AUTOSAR XML (schema 4-2-2)
package /STELLANTIS/EPT/ASWCs
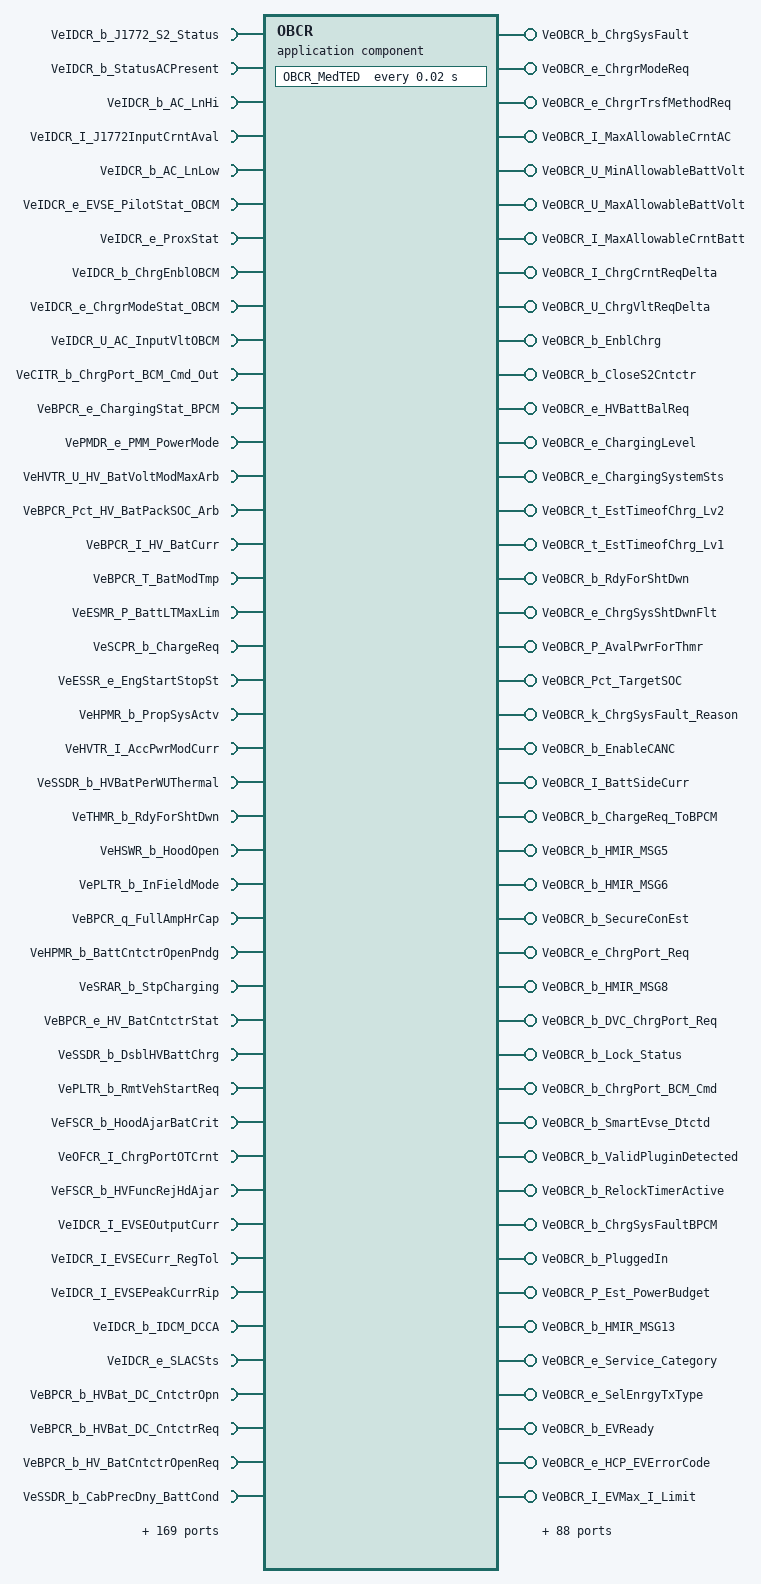
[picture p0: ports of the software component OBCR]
  application sw component type OBCR
    179 x require port:
      VeIDCR_b_J1772_S2_Status: variation-point={short-label=vpVeIDCR_b_J1772_S2_Status, sw-syscond=1}, nonqueued-receiver-com-spec{data-element=Value, init-value=0}, required-interface=VeIDCR_b_J1772_S2_Status
      VeIDCR_b_StatusACPresent: variation-point={short-label=vpVeIDCR_b_StatusACPresent, sw-syscond=1}, nonqueued-receiver-com-spec{data-element=Value, init-value=0}, required-interface=VeIDCR_b_StatusACPresent
      VeIDCR_b_AC_LnHi: variation-point={short-label=vpVeIDCR_b_AC_LnHi, sw-syscond=1}, nonqueued-receiver-com-spec{data-element=Value, init-value=0}, required-interface=VeIDCR_b_AC_LnHi
      VeIDCR_I_J1772InputCrntAval: variation-point={short-label=vpVeIDCR_I_J1772InputCrntAval, sw-syscond=1}, nonqueued-receiver-com-spec{data-element=Value, init-value=0}, required-interface=VeIDCR_I_J1772InputCrntAval
      VeIDCR_b_AC_LnLow: variation-point={short-label=vpVeIDCR_b_AC_LnLow, sw-syscond=1}, nonqueued-receiver-com-spec{data-element=Value, init-value=0}, required-interface=VeIDCR_b_AC_LnLow
      VeIDCR_e_EVSE_PilotStat_OBCM: nonqueued-receiver-com-spec{data-element=Value, init-value=CeOBCR_e_NO_EVSE_OBCM}, required-interface=VeIDCR_e_EVSE_PilotStat_OBCM
      VeIDCR_e_ProxStat: nonqueued-receiver-com-spec{data-element=Value, init-value=CeOBCR_e_ProxLo_OBCM}, required-interface=VeIDCR_e_ProxStat
      VeIDCR_b_ChrgEnblOBCM: nonqueued-receiver-com-spec{data-element=Value, init-value=0}, required-interface=VeIDCR_b_ChrgEnblOBCM
      VeIDCR_e_ChrgrModeStat_OBCM: variation-point={short-label=vpVeIDCR_e_ChrgrModeStat_OBCM, sw-syscond=1}, nonqueued-receiver-com-spec{data-element=Value, init-value=CeOBCR_e_Idle_OBCM}, required-interface=VeIDCR_e_ChrgrModeStat_OBCM
      VeIDCR_U_AC_InputVltOBCM: variation-point={short-label=vpVeIDCR_U_AC_InputVltOBCM, sw-syscond=1}, nonqueued-receiver-com-spec{data-element=Value, init-value=0}, required-interface=VeIDCR_U_AC_InputVltOBCM
      VeCITR_b_ChrgPort_BCM_Cmd_Out: variation-point={short-label=vpVeCITR_b_ChrgPort_BCM_Cmd_Out, sw-syscond=1}, nonqueued-receiver-com-spec{data-element=Value, init-value=0}, required-interface=VeCITR_b_ChrgPort_BCM_Cmd_Out
      VeBPCR_e_ChargingStat_BPCM: nonqueued-receiver-com-spec{data-element=Value, init-value=CeOBCR_e_BattNotReady}, required-interface=VeBPCR_e_ChargingStat_BPCM
      VePMDR_e_PMM_PowerMode: variation-point={short-label=vpVePMDR_e_PMM_PowerMode, sw-syscond=1}, nonqueued-receiver-com-spec{data-element=Value, init-value=CePMDR_e_PowerMode_Off}, required-interface=VePMDR_e_PMM_PowerMode
      VeHVTR_U_HV_BatVoltModMaxArb: nonqueued-receiver-com-spec{data-element=Value, init-value=0}, required-interface=VeHVTR_U_HV_BatVoltModMaxArb
      VeBPCR_Pct_HV_BatPackSOC_Arb: variation-point={short-label=vpVeBPCR_Pct_HV_BatPackSOC_Arb, sw-syscond=1}, nonqueued-receiver-com-spec{data-element=Value, init-value=0}, required-interface=VeBPCR_Pct_HV_BatPackSOC_Arb
      VeBPCR_I_HV_BatCurr: variation-point={short-label=vpVeBPCR_I_HV_BatCurr, sw-syscond=1}, nonqueued-receiver-com-spec{data-element=Value, init-value=0}, required-interface=VeBPCR_I_HV_BatCurr
      VeBPCR_T_BatModTmp: variation-point={short-label=vpVeBPCR_T_BatModTmp, sw-syscond=1}, nonqueued-receiver-com-spec{data-element=Value, init-value=0}, required-interface=VeBPCR_T_BatModTmp
      VeESMR_P_BattLTMaxLim: variation-point={short-label=vpVeESMR_P_BattLTMaxLim, sw-syscond=1}, nonqueued-receiver-com-spec{data-element=Value, init-value=0}, required-interface=VeESMR_P_BattLTMaxLim
      VeSCPR_b_ChargeReq: nonqueued-receiver-com-spec{data-element=Value, init-value=0}, required-interface=VeSCPR_b_ChargeReq
      VeESSR_e_EngStartStopSt: variation-point={short-label=vpVeESSR_e_EngStartStopSt, sw-syscond=1}, nonqueued-receiver-com-spec{data-element=Value, init-value=CeESSR_e_EngOff}, required-interface=VeESSR_e_EngStartStopSt
      VeHPMR_b_PropSysActv: nonqueued-receiver-com-spec{data-element=Value, init-value=0}, required-interface=VeHPMR_b_PropSysActv
      VeHVTR_I_AccPwrModCurr: nonqueued-receiver-com-spec{data-element=Value, init-value=0}, required-interface=VeHVTR_I_AccPwrModCurr
      VeSSDR_b_HVBatPerWUThermal: nonqueued-receiver-com-spec{data-element=Value, init-value=0}, required-interface=VeSSDR_b_HVBatPerWUThermal
      VeTHMR_b_RdyForShtDwn: nonqueued-receiver-com-spec{data-element=Value, init-value=0}, required-interface=VeTHMR_b_RdyForShtDwn
      VeHSWR_b_HoodOpen: nonqueued-receiver-com-spec{data-element=Value, init-value=0}, required-interface=VeHSWR_b_HoodOpen
      VePLTR_b_InFieldMode: nonqueued-receiver-com-spec{data-element=Value, init-value=0}, required-interface=VePLTR_b_InFieldMode
      VeBPCR_q_FullAmpHrCap: nonqueued-receiver-com-spec{data-element=Value, init-value=0}, required-interface=VeBPCR_q_FullAmpHrCap
      VeHPMR_b_BattCntctrOpenPndg: variation-point={short-label=vpVeHPMR_b_BattCntctrOpenPndg, sw-syscond=1}, nonqueued-receiver-com-spec{data-element=Value, init-value=0}, required-interface=VeHPMR_b_BattCntctrOpenPndg
      VeSRAR_b_StpCharging: variation-point={short-label=vpVeSRAR_b_StpCharging, sw-syscond=1}, nonqueued-receiver-com-spec{data-element=Value, init-value=0}, required-interface=VeSRAR_b_StpCharging
      VeBPCR_e_HV_BatCntctrStat: variation-point={short-label=vpVeBPCR_e_HV_BatCntctrStat, sw-syscond=1}, nonqueued-receiver-com-spec{data-element=Value, init-value=CeHVTR_e_Open}, required-interface=VeBPCR_e_HV_BatCntctrStat
      VeSSDR_b_DsblHVBattChrg: variation-point={short-label=vpVeSSDR_b_DsblHVBattChrg, sw-syscond=1}, nonqueued-receiver-com-spec{data-element=Value, init-value=0}, required-interface=VeSSDR_b_DsblHVBattChrg
      VePLTR_b_RmtVehStartReq: variation-point={short-label=vpVePLTR_b_RmtVehStartReq, sw-syscond=1}, nonqueued-receiver-com-spec{data-element=Value, init-value=0}, required-interface=VePLTR_b_RmtVehStartReq
      VeFSCR_b_HoodAjarBatCrit: nonqueued-receiver-com-spec{data-element=Value, init-value=0}, required-interface=VeFSCR_b_HoodAjarBatCrit
      VeOFCR_I_ChrgPortOTCrnt: variation-point={short-label=vpVeOFCR_I_ChrgPortOTCrnt, sw-syscond=1}, nonqueued-receiver-com-spec{data-element=Value, init-value=0}, required-interface=VeOFCR_I_ChrgPortOTCrnt
      VeFSCR_b_HVFuncRejHdAjar: variation-point={short-label=vpVeFSCR_b_HVFuncRejHdAjar, sw-syscond=1}, nonqueued-receiver-com-spec{data-element=Value, init-value=0}, required-interface=VeFSCR_b_HVFuncRejHdAjar
      VeIDCR_I_EVSEOutputCurr: nonqueued-receiver-com-spec{data-element=Value, init-value=0}, required-interface=VeIDCR_I_EVSEOutputCurr
      VeIDCR_I_EVSECurr_RegTol: nonqueued-receiver-com-spec{data-element=Value, init-value=0}, required-interface=VeIDCR_I_EVSECurr_RegTol
      VeIDCR_I_EVSEPeakCurrRip: nonqueued-receiver-com-spec{data-element=Value, init-value=0}, required-interface=VeIDCR_I_EVSEPeakCurrRip
      VeIDCR_b_IDCM_DCCA: nonqueued-receiver-com-spec{data-element=Value, init-value=0}, required-interface=VeIDCR_b_IDCM_DCCA
      VeIDCR_e_SLACSts: nonqueued-receiver-com-spec{data-element=Value, init-value=CeIDCR_e_SLACSts_EVSE_NtFnd}, required-interface=VeIDCR_e_SLACSts
      VeBPCR_b_HVBat_DC_CntctrOpn: nonqueued-receiver-com-spec{data-element=Value, init-value=0}, required-interface=VeBPCR_b_HVBat_DC_CntctrOpn
      VeBPCR_b_HVBat_DC_CntctrReq: nonqueued-receiver-com-spec{data-element=Value, init-value=0}, required-interface=VeBPCR_b_HVBat_DC_CntctrReq
      VeBPCR_b_HV_BatCntctrOpenReq: nonqueued-receiver-com-spec{data-element=Value, init-value=0}, required-interface=VeBPCR_b_HV_BatCntctrOpenReq
      VeSSDR_b_CabPrecDny_BattCond: nonqueued-receiver-com-spec{data-element=Value, init-value=0}, required-interface=VeSSDR_b_CabPrecDny_BattCond
      VeBPCR_b_HV_BatCntctrOpenPending: nonqueued-receiver-com-spec{data-element=Value, init-value=0}, required-interface=VeBPCR_b_HV_BatCntctrOpenPending
      VePLTR_e_ShippingMode: nonqueued-receiver-com-spec{data-element=Value, init-value=CePLTR_e_ShipingMode_CUST_MD}, required-interface=VePLTR_e_ShippingMode
      VeESMR_Pct_IP_SOCSetPt: variation-point={short-label=vpVeESMR_Pct_IP_SOCSetPt, sw-syscond=1}, nonqueued-receiver-com-spec{data-element=Value, init-value=0}, required-interface=VeESMR_Pct_IP_SOCSetPt
      VeENGR_T_EngCoolantTemp: variation-point={short-label=vpVeENGR_T_EngCoolantTemp, sw-syscond=1}, nonqueued-receiver-com-spec{data-element=Value, init-value=0}, required-interface=VeENGR_T_EngCoolantTemp
      VeENGR_b_ECT_Sgnl_Rcvd: variation-point={short-label=vpVeENGR_b_ECT_Sgnl_Rcvd, sw-syscond=1}, nonqueued-receiver-com-spec{data-element=Value, init-value=0}, required-interface=VeENGR_b_ECT_Sgnl_Rcvd
      VeHMIR_Pct_HVBatSOC_HCP: variation-point={short-label=vpVeHMIR_Pct_HVBatSOC_HCP, sw-syscond=1}, nonqueued-receiver-com-spec{data-element=Value, init-value=0}, required-interface=VeHMIR_Pct_HVBatSOC_HCP
      VeESMR_Pct_Logistics_SOCSetPt: variation-point={short-label=vpVeESMR_Pct_Logistics_SOCSetPt, sw-syscond=1}, nonqueued-receiver-com-spec{data-element=Value, init-value=0}, required-interface=VeESMR_Pct_Logistics_SOCSetPt
      VeIDCR_e_Prox_GBT: nonqueued-receiver-com-spec{data-element=Value, init-value=CeIDCR_e_CC_LO}, required-interface=VeIDCR_e_Prox_GBT
      VeIDCR_e_TxGBTMsgResponse: nonqueued-receiver-com-spec{data-element=Value, init-value=CeIDCR_e_GBTRes_EVSE_Not_Connected}, required-interface=VeIDCR_e_TxGBTMsgResponse
      VeIDCR_e_TxGBTMsgRequest: nonqueued-receiver-com-spec{data-element=Value, init-value=CeIDCR_e_GBTReq_EVSE_Not_Connected}, required-interface=VeIDCR_e_TxGBTMsgRequest
      VeIDCR_b_V2L_Detected: nonqueued-receiver-com-spec{data-element=Value, init-value=0}, required-interface=VeIDCR_b_V2L_Detected
      VeVTLR_e_DschrgOBCMdRq: nonqueued-receiver-com-spec{data-element=Value, init-value=CeOBCR_e_Idle_OBCMdRq}, required-interface=VeVTLR_e_DschrgOBCMdRq
      VeVTLR_b_DschrgS2Cmd: nonqueued-receiver-com-spec{data-element=Value, init-value=0}, required-interface=VeVTLR_b_DschrgS2Cmd
      VeVTLR_e_DschrgSysSts: nonqueued-receiver-com-spec{data-element=Value, init-value=CeVTLR_e_DschrgInactv}, required-interface=VeVTLR_e_DschrgSysSts
      VeFCPR_b_FCPS_H2_RefuelSts: variation-point={short-label=vpVeFCPR_b_FCPS_H2_RefuelSts, sw-syscond=1}, nonqueued-receiver-com-spec{data-element=Value, init-value=0}, required-interface=VeFCPR_b_FCPS_H2_RefuelSts
      VeSSDR_b_KeepHotCold_PCC: variation-point={short-label=vpVeSSDR_b_KeepHotCold_PCC, sw-syscond=1}, nonqueued-receiver-com-spec{data-element=Value, init-value=0}, required-interface=VeSSDR_b_KeepHotCold_PCC
      VeDMAB_y_StatusByte_LostCommBCCM: nonqueued-receiver-com-spec{data-element=Value, init-value=0}, required-interface=VeDMAB_y_StatusByte_LostCommBCCM
      VeDMAB_y_StatusByte_LostCommIDCM: nonqueued-receiver-com-spec{data-element=Value, init-value=0}, required-interface=VeDMAB_y_StatusByte_LostCommIDCM
      VeDMAB_y_StatusByte_LostCommOBCM: nonqueued-receiver-com-spec{data-element=Value, init-value=0}, required-interface=VeDMAB_y_StatusByte_LostCommOBCM
      VeDMAB_y_StatusByte_LostComm_IDCM_CANC11: nonqueued-receiver-com-spec{data-element=Value, init-value=0}, required-interface=VeDMAB_y_StatusByte_LostComm_IDCM_CANC11
      VeINVR_I_MtrA_DC_Crnt: variation-point={short-label=vpVeINVR_I_MtrA_DC_Crnt, sw-syscond=1}, nonqueued-receiver-com-spec{data-element=Value, init-value=0}, required-interface=VeINVR_I_MtrA_DC_Crnt
      VeHVTR_P_HV_AccPwr: variation-point={short-label=vpVeHVTR_P_HV_AccPwr, sw-syscond=1}, nonqueued-receiver-com-spec{data-element=Value, init-value=0}, required-interface=VeHVTR_P_HV_AccPwr
      VeINVR_U_MtrA_DC_Volt: variation-point={short-label=vpVeINVR_U_MtrA_DC_Volt, sw-syscond=1}, nonqueued-receiver-com-spec{data-element=Value, init-value=0}, required-interface=VeINVR_U_MtrA_DC_Volt
      VeHVTR_P_AccPwrModPwr: variation-point={short-label=vpVeHVTR_P_AccPwrModPwr, sw-syscond=1}, nonqueued-receiver-com-spec{data-element=Value, init-value=0}, required-interface=VeHVTR_P_AccPwrModPwr
      VeIDCR_b_V2X_Sts: variation-point={short-label=vpVeIDCR_b_V2X_Sts, sw-syscond=1}, nonqueued-receiver-com-spec{data-element=Value, init-value=0}, required-interface=VeIDCR_b_V2X_Sts
      VeVDVR_b_DschrgS2Cmd: variation-point={short-label=vpVeVDVR_b_DschrgS2Cmd, sw-syscond=1}, nonqueued-receiver-com-spec{data-element=Value, init-value=0}, required-interface=VeVDVR_b_DschrgS2Cmd
      VeVTLR_b_OnboardPP1_Dtctd: nonqueued-receiver-com-spec{data-element=Value, init-value=0}, required-interface=VeVTLR_b_OnboardPP1_Dtctd
      VeVTLR_b_ACSwSts: variation-point={short-label=vpVeVTLR_b_ACSwSts, sw-syscond=1}, nonqueued-receiver-com-spec{data-element=Value, init-value=0}, required-interface=VeVTLR_b_ACSwSts
      VeVDVR_b_V2VChrgPortReq: variation-point={short-label=vpVeVDVR_b_V2VChrgPortReq, sw-syscond=1}, nonqueued-receiver-com-spec{data-element=Value, init-value=0}, required-interface=VeVDVR_b_V2VChrgPortReq
      VeVDVR_b_V2V_Detected: variation-point={short-label=vpVeVDVR_b_V2V_Detected, sw-syscond=1}, nonqueued-receiver-com-spec{data-element=Value, init-value=0}, required-interface=VeVDVR_b_V2V_Detected
      VeVTLR_e_DschrgOBCMdRq_Onboard: nonqueued-receiver-com-spec{data-element=Value, init-value=CeOBCR_e_Idle_OBCMdRq}, required-interface=VeVTLR_e_DschrgOBCMdRq_Onboard
      VeVDVR_e_DschrgOBCMdRq: nonqueued-receiver-com-spec{data-element=Value, init-value=CeOBCR_e_Idle_OBCMdRq}, required-interface=VeVDVR_e_DschrgOBCMdRq
      VeHVTR_U_HvBattVolt_Min: variation-point={short-label=vpVeHVTR_U_HvBattVolt_Min, sw-syscond=1}, nonqueued-receiver-com-spec{data-element=Value, init-value=0}, required-interface=VeHVTR_U_HvBattVolt_Min
      VeTIMR_e_RacePrepRaceTypeSts: variation-point={short-label=vpVeTIMR_e_RacePrepRaceTypeSts, sw-syscond=1}, nonqueued-receiver-com-spec{data-element=Value, init-value=CeTIMR_e_RaceType_Drag}, required-interface=VeTIMR_e_RacePrepRaceTypeSts
      VeTIMR_e_RacePrep: variation-point={short-label=vpVeTIMR_e_RacePrep, sw-syscond=1}, nonqueued-receiver-com-spec{data-element=Value, init-value=CeTIMR_e_RacePrep_Off}, required-interface=VeTIMR_e_RacePrep
      VeBPCR_e_HVTracBatCntctrConfig: nonqueued-receiver-com-spec{data-element=Value, init-value=CeBPCR_e_HVTracBatConfig_Closed_Parallel}, required-interface=VeBPCR_e_HVTracBatCntctrConfig
      VeBPCR_b_HV_AuxLoadOffReq: nonqueued-receiver-com-spec{data-element=Value, init-value=0}, required-interface=VeBPCR_b_HV_AuxLoadOffReq
      VeCCCR_b_SOC_LvlSet_80: nonqueued-receiver-com-spec{data-element=Value, init-value=0}, required-interface=VeCCCR_b_SOC_LvlSet_80
      VeCHFR_v_ModifiedVehSpeed: variation-point={short-label=vpVeCHFR_v_ModifiedVehSpeed, sw-syscond=1}, nonqueued-receiver-com-spec{data-element=Value, init-value=0}, required-interface=VeCHFR_v_ModifiedVehSpeed
      VeCHFR_b_ACPrnt_S2Open: variation-point={short-label=vpVeCHFR_b_ACPrnt_S2Open, sw-syscond=1}, nonqueued-receiver-com-spec{data-element=Value, init-value=0}, required-interface=VeCHFR_b_ACPrnt_S2Open
      VeCCCR_I_ChrgTypeHWLim: variation-point={short-label=vpVeCCCR_I_ChrgTypeHWLim, sw-syscond=1}, nonqueued-receiver-com-spec{data-element=Value, init-value=0}, required-interface=VeCCCR_I_ChrgTypeHWLim
      VeCCCR_I_BattCommandedCurr: variation-point={short-label=vpVeCCCR_I_BattCommandedCurr, sw-syscond=1}, nonqueued-receiver-com-spec{data-element=Value, init-value=0}, required-interface=VeCCCR_I_BattCommandedCurr
      VeCPLR_e_ChrgPort_Req: nonqueued-receiver-com-spec{data-element=Value, init-value=CeOBCR_e_PortNoRequest}, required-interface=VeCPLR_e_ChrgPort_Req
      VeCCCR_b_PwrLevActive: variation-point={short-label=vpVeCCCR_b_PwrLevActive, sw-syscond=1}, nonqueued-receiver-com-spec{data-element=Value, init-value=0}, required-interface=VeCCCR_b_PwrLevActive
      VeCCCR_e_PwrLevSet: nonqueued-receiver-com-spec{data-element=Value, init-value=CeOBCR_e_PwrLimReq_SNA}, required-interface=VeCCCR_e_PwrLevSet
      VeCCCR_I_MaxAllowedCurr: nonqueued-receiver-com-spec{data-element=Value, init-value=0}, required-interface=VeCCCR_I_MaxAllowedCurr
      VeCHFR_b_CANC_WU_NCV: variation-point={short-label=vpVeCHFR_b_CANC_WU_NCV, sw-syscond=1}, nonqueued-receiver-com-spec{data-element=Value, init-value=0}, required-interface=VeCHFR_b_CANC_WU_NCV
      VeCCCR_I_HWCurrentBound: variation-point={short-label=vpVeCCCR_I_HWCurrentBound, sw-syscond=1}, nonqueued-receiver-com-spec{data-element=Value, init-value=0}, required-interface=VeCCCR_I_HWCurrentBound
      VeCCCR_I_PLS_ReducedCurr: variation-point={short-label=vpVeCCCR_I_PLS_ReducedCurr, sw-syscond=1}, nonqueued-receiver-com-spec{data-element=Value, init-value=0}, required-interface=VeCCCR_I_PLS_ReducedCurr
      VeCHFR_b_ChrgSysFault: nonqueued-receiver-com-spec{data-element=Value, init-value=0}, required-interface=VeCHFR_b_ChrgSysFault
      VeDCCR_b_V2GPilotEnable: variation-point={short-label=vpVeDCCR_b_V2GPilotEnable, sw-syscond=1}, nonqueued-receiver-com-spec{data-element=Value, init-value=0}, required-interface=VeDCCR_b_V2GPilotEnable
      VeDCCR_e_DCChrgSysStat_SF: variation-point={short-label=vpVeDCCR_e_DCChrgSysStat_SF, sw-syscond=1}, nonqueued-receiver-com-spec{data-element=Value, init-value=CeOBCR_e_DCinit}, required-interface=VeDCCR_e_DCChrgSysStat_SF
      VeCHFR_b_Reset_Charging: variation-point={short-label=vpVeCHFR_b_Reset_Charging, sw-syscond=1}, nonqueued-receiver-com-spec{data-element=Value, init-value=0}, required-interface=VeCHFR_b_Reset_Charging
      VeCHFR_b_GiveUp: variation-point={short-label=vpVeCHFR_b_GiveUp, sw-syscond=1}, nonqueued-receiver-com-spec{data-element=Value, init-value=0}, required-interface=VeCHFR_b_GiveUp
      VeDCCR_e_DCGBTChrgSysStat: variation-point={short-label=vpVeDCCR_e_DCGBTChrgSysStat, sw-syscond=1}, nonqueued-receiver-com-spec{data-element=Value, init-value=CeOBCR_e_DCGBTinit}, required-interface=VeDCCR_e_DCGBTChrgSysStat
      VeDCCR_b_J1772_S2_Close_DC_SF: variation-point={short-label=vpVeDCCR_b_J1772_S2_Close_DC_SF, sw-syscond=1}, nonqueued-receiver-com-spec{data-element=Value, init-value=0}, required-interface=VeDCCR_b_J1772_S2_Close_DC_SF
      VeCHFR_b_ChargingFault: variation-point={short-label=vpVeCHFR_b_ChargingFault, sw-syscond=1}, nonqueued-receiver-com-spec{data-element=Value, init-value=0}, required-interface=VeCHFR_b_ChargingFault
      VeCCCR_b_ChrgCmplteCondtnMet: variation-point={short-label=vpVeCCCR_b_ChrgCmplteCondtnMet, sw-syscond=1}, nonqueued-receiver-com-spec{data-element=Value, init-value=0}, required-interface=VeCCCR_b_ChrgCmplteCondtnMet
      VeCPLR_b_InternalLockReq: variation-point={short-label=vpVeCPLR_b_InternalLockReq, sw-syscond=1}, nonqueued-receiver-com-spec{data-element=Value, init-value=0}, required-interface=VeCPLR_b_InternalLockReq
      VeCPLR_b_RelockTimerActive: nonqueued-receiver-com-spec{data-element=Value, init-value=0}, required-interface=VeCPLR_b_RelockTimerActive
      VeCPLR_b_Lock_Status: nonqueued-receiver-com-spec{data-element=Value, init-value=0}, required-interface=VeCPLR_b_Lock_Status
      VeCPLR_k_ChrgPortEnbl_BSW: nonqueued-receiver-com-spec{data-element=Value, init-value=0}, required-interface=VeCPLR_k_ChrgPortEnbl_BSW
      VeCPLR_b_ChrgPortReq_BSW: nonqueued-receiver-com-spec{data-element=Value, init-value=0}, required-interface=VeCPLR_b_ChrgPortReq_BSW
      VeCPLR_b_DVC_ChrgPort_Req: nonqueued-receiver-com-spec{data-element=Value, init-value=0}, required-interface=VeCPLR_b_DVC_ChrgPort_Req
      VeCPLR_b_HMIR_MSG13: nonqueued-receiver-com-spec{data-element=Value, init-value=0}, required-interface=VeCPLR_b_HMIR_MSG13
      VeCPLR_e_ChargePortLock_Sts: nonqueued-receiver-com-spec{data-element=Value, init-value=CeOBCR_e_PortLockSts_Default}, required-interface=VeCPLR_e_ChargePortLock_Sts
      VeCCCR_I_ChrgCrntReqDelta: nonqueued-receiver-com-spec{data-element=Value, init-value=0}, required-interface=VeCCCR_I_ChrgCrntReqDelta
      VeCCCR_e_HVBattBalReq: nonqueued-receiver-com-spec{data-element=Value, init-value=CeOBCR_e_NoRequest}, required-interface=VeCCCR_e_HVBattBalReq
      VeCCCR_e_BattPckVoltRchd_BST: nonqueued-receiver-com-spec{data-element=Value, init-value=CeOBCR_e_BattPckVolt_NotReached}, required-interface=VeCCCR_e_BattPckVoltRchd_BST
      VeCCCR_e_SOCRchd_BST: nonqueued-receiver-com-spec{data-element=Value, init-value=CeOBCR_e_SOC_NotReached}, required-interface=VeCCCR_e_SOCRchd_BST
      VeCCCR_e_MaxCellVoltRchd_BST: nonqueued-receiver-com-spec{data-element=Value, init-value=CeOBCR_e_MaxCellVolt_NotReached}, required-interface=VeCCCR_e_MaxCellVoltRchd_BST
      VeCCCR_P_PLS_PwrLev{1..5}: nonqueued-receiver-com-spec{data-element=Value, init-value=0}, required-interface=VeCCCR_P_PLS_PwrLev{1..5}
      VeCHFR_U_ChrgVltReqDelta: nonqueued-receiver-com-spec{data-element=Value, init-value=0}, required-interface=VeCHFR_U_ChrgVltReqDelta
      VeCHFR_k_ChrgSysFault_Reason: nonqueued-receiver-com-spec{data-element=Value, init-value=0}, required-interface=VeCHFR_k_ChrgSysFault_Reason
      VeCHFR_I_BattSideCurr: nonqueued-receiver-com-spec{data-element=Value, init-value=0}, required-interface=VeCHFR_I_BattSideCurr
      VeCHFR_b_ChargeReq_ToBPCM: nonqueued-receiver-com-spec{data-element=Value, init-value=0}, required-interface=VeCHFR_b_ChargeReq_ToBPCM
      VeCHFR_b_HMIR_MSG5: nonqueued-receiver-com-spec{data-element=Value, init-value=0}, required-interface=VeCHFR_b_HMIR_MSG5
      VeCHFR_b_HMIR_MSG6: nonqueued-receiver-com-spec{data-element=Value, init-value=0}, required-interface=VeCHFR_b_HMIR_MSG6
      VeCHFR_b_HMIR_MSG8: nonqueued-receiver-com-spec{data-element=Value, init-value=0}, required-interface=VeCHFR_b_HMIR_MSG8
      VeCHFR_b_ChrgSysFaultBPCM: nonqueued-receiver-com-spec{data-element=Value, init-value=0}, required-interface=VeCHFR_b_ChrgSysFaultBPCM
      VeCHFR_K_ChargingFailure{1..5}: nonqueued-receiver-com-spec{data-element=Value, init-value=0}, required-interface=VeCHFR_K_ChargingFailure{1..5}
      VeDCCR_e_Service_Category: nonqueued-receiver-com-spec{data-element=Value, init-value=0}, required-interface=VeDCCR_e_Service_Category
      VeDCCR_e_SelEnrgyTxType: nonqueued-receiver-com-spec{data-element=Value, init-value=0}, required-interface=VeDCCR_e_SelEnrgyTxType
      VeDCCR_b_EVReady: nonqueued-receiver-com-spec{data-element=Value, init-value=0}, required-interface=VeDCCR_b_EVReady
      VeDCCR_e_HCP_EVErrorCode: nonqueued-receiver-com-spec{data-element=Value, init-value=0}, required-interface=VeDCCR_e_HCP_EVErrorCode
      VeDCCR_I_EVMax_I_Limit: nonqueued-receiver-com-spec{data-element=Value, init-value=0}, required-interface=VeDCCR_I_EVMax_I_Limit
      VeDCCR_P_EVMax_P_Limit: nonqueued-receiver-com-spec{data-element=Value, init-value=0}, required-interface=VeDCCR_P_EVMax_P_Limit
      VeDCCR_U_EVMax_V_Limit: nonqueued-receiver-com-spec{data-element=Value, init-value=0}, required-interface=VeDCCR_U_EVMax_V_Limit
      VeDCCR_E_EVEnergyCapacity: nonqueued-receiver-com-spec{data-element=Value, init-value=0}, required-interface=VeDCCR_E_EVEnergyCapacity
      VeDCCR_b_DC_Isolation_Cmd: nonqueued-receiver-com-spec{data-element=Value, init-value=0}, required-interface=VeDCCR_b_DC_Isolation_Cmd
      VeDCCR_e_DC_CntctrCmd: nonqueued-receiver-com-spec{data-element=Value, init-value=CeOBCR_e_DCCntctr_Open}, required-interface=VeDCCR_e_DC_CntctrCmd
      VeDCCR_U_EV_DCTargetVolt: nonqueued-receiver-com-spec{data-element=Value, init-value=0}, required-interface=VeDCCR_U_EV_DCTargetVolt
      VeDCCR_b_WeldChkComplete: nonqueued-receiver-com-spec{data-element=Value, init-value=0}, required-interface=VeDCCR_b_WeldChkComplete
      VeDCCR_b_RdyToChrgSt: nonqueued-receiver-com-spec{data-element=Value, init-value=0}, required-interface=VeDCCR_b_RdyToChrgSt
      VeDCCR_K_SelectedServiceID: nonqueued-receiver-com-spec{data-element=Value, init-value=0}, required-interface=VeDCCR_K_SelectedServiceID
      VeDCCR_e_SelPayOptn: nonqueued-receiver-com-spec{data-element=Value, init-value=CeOBCR_e_NoPaymentSel}, required-interface=VeDCCR_e_SelPayOptn
      VeDCCR_b_HCP_SessionStpCmd: nonqueued-receiver-com-spec{data-element=Value, init-value=0}, required-interface=VeDCCR_b_HCP_SessionStpCmd
      VeDCCR_e_DCChrg_TestSts: nonqueued-receiver-com-spec{data-element=Value, init-value=CeOBCR_e_DCChrg_TestSts_NotInit}, required-interface=VeDCCR_e_DCChrg_TestSts
      VeDCCR_b_DCChrgInitialization: nonqueued-receiver-com-spec{data-element=Value, init-value=0}, required-interface=VeDCCR_b_DCChrgInitialization
      VeDCCR_e_CellVolt_OOR: nonqueued-receiver-com-spec{data-element=Value, init-value=CeOBCR_e_CellVoltStat_Normal}, required-interface=VeDCCR_e_CellVolt_OOR
      VeDCCR_e_ChrgCurr_OOR: nonqueued-receiver-com-spec{data-element=Value, init-value=CeOBCR_e_ChrgCurrStat_Normal}, required-interface=VeDCCR_e_ChrgCurr_OOR
      VeDCCR_e_BattTemp_OOR: nonqueued-receiver-com-spec{data-element=Value, init-value=CeOBCR_e_BattTempStat_Normal}, required-interface=VeDCCR_e_BattTemp_OOR
      VeDCCR_e_SOC_OOR: nonqueued-receiver-com-spec{data-element=Value, init-value=CeOBCR_e_BattSOCStat_Normal}, required-interface=VeDCCR_e_SOC_OOR
      VeDCCR_b_CPIM_Error: nonqueued-receiver-com-spec{data-element=Value, init-value=0}, required-interface=VeDCCR_b_CPIM_Error
      VeDCCR_b_CPIM_OT: nonqueued-receiver-com-spec{data-element=Value, init-value=0}, required-interface=VeDCCR_b_CPIM_OT
      VeDCCR_Pct_BattFullSOC: nonqueued-receiver-com-spec{data-element=Value, init-value=0}, required-interface=VeDCCR_Pct_BattFullSOC
      VeDCCR_b_BattOverVolt: nonqueued-receiver-com-spec{data-element=Value, init-value=0}, required-interface=VeDCCR_b_BattOverVolt
      VeDCCR_b_BattUnderVolt: nonqueued-receiver-com-spec{data-element=Value, init-value=0}, required-interface=VeDCCR_b_BattUnderVolt
      VeDCCR_b_DCGBTReadyToCharge: nonqueued-receiver-com-spec{data-element=Value, init-value=0}, required-interface=VeDCCR_b_DCGBTReadyToCharge
      VeDCCR_b_DCGBTEVChrgPermit: nonqueued-receiver-com-spec{data-element=Value, init-value=0}, required-interface=VeDCCR_b_DCGBTEVChrgPermit
      VeDCCR_T_GBT_MaxBattTempAllwd: nonqueued-receiver-com-spec{data-element=Value, init-value=0}, required-interface=VeDCCR_T_GBT_MaxBattTempAllwd
      VeDCCR_e_GBT_ChrgCntrolMethod: nonqueued-receiver-com-spec{data-element=Value, init-value=CeOBCR_e_ChrgMthd_Init}, required-interface=VeDCCR_e_GBT_ChrgCntrolMethod
      VeDCCR_e_GBT_ChrgrInterrupt: nonqueued-receiver-com-spec{data-element=Value, init-value=CeOBCR_e_NoChrgrInterrupt}, required-interface=VeDCCR_e_GBT_ChrgrInterrupt
      VeDCCR_e_SelectAppProtocol: nonqueued-receiver-com-spec{data-element=Value, init-value=CeOBCR_e_DIN}, required-interface=VeDCCR_e_SelectAppProtocol
      VeDCCR_b_SelectSecProtocol: nonqueued-receiver-com-spec{data-element=Value, init-value=0}, required-interface=VeDCCR_b_SelectSecProtocol
      VeDCCR_e_ChargeProgress: nonqueued-receiver-com-spec{data-element=Value, init-value=CeOBCR_e_No_Request}, required-interface=VeDCCR_e_ChargeProgress
      VeDCCR_e_DC_ChrgTypeCmd: nonqueued-receiver-com-spec{data-element=Value, init-value=CeOBCR_e_DC_ChrgType_Null}, required-interface=VeDCCR_e_DC_ChrgTypeCmd
      VeVDVR_b_Secure_V2VConnected: variation-point={short-label=vpVeVDVR_b_Secure_V2VConnected, sw-syscond=1}, nonqueued-receiver-com-spec{data-element=Value, init-value=0}, required-interface=VeVDVR_b_Secure_V2VConnected
      VeVDVR_b_Secure_V2LConnected: variation-point={short-label=vpVeVDVR_b_Secure_V2LConnected, sw-syscond=1}, nonqueued-receiver-com-spec{data-element=Value, init-value=0}, required-interface=VeVDVR_b_Secure_V2LConnected
      VeVTHR_b_Rdy4shutdown: variation-point={short-label=vpVeVTHR_b_Rdy4shutdown, sw-syscond=1}, nonqueued-receiver-com-spec{data-element=Value, init-value=0}, required-interface=VeVTHR_b_Rdy4shutdown
      VeVTHR_b_V2H_Active: variation-point={short-label=vpVeVTHR_b_V2H_Active, sw-syscond=1}, nonqueued-receiver-com-spec{data-element=Value, init-value=0}, required-interface=VeVTHR_b_V2H_Active
      VeDCCR_b_PnCFailure: nonqueued-receiver-com-spec{data-element=Value, init-value=0}, required-interface=VeDCCR_b_PnCFailure
      VeDCCR_b_PnCRetryFail: nonqueued-receiver-com-spec{data-element=Value, init-value=0}, required-interface=VeDCCR_b_PnCRetryFail
      VeDCCR_e_Protocol_Priority{1..3}: nonqueued-receiver-com-spec{data-element=Value, init-value=CeOBCR_e_No_Protocol}, required-interface=VeDCCR_e_Protocol_Priority{1..3}
      VeDCCR_k_MaxEntriesSASScheduleTuple: nonqueued-receiver-com-spec{data-element=Value, init-value=0}, required-interface=VeDCCR_k_MaxEntriesSASScheduleTuple
    133 x provide port:
      VeOBCR_b_ChrgSysFault: nonqueued-sender-com-spec{data-element=Value, init-value=0}, provided-interface=VeOBCR_b_ChrgSysFault
      VeOBCR_e_ChrgrModeReq: nonqueued-sender-com-spec{data-element=Value, init-value=CeOBCR_e_Idle_OBCMdRq}, provided-interface=VeOBCR_e_ChrgrModeReq
      VeOBCR_e_ChrgrTrsfMethodReq: nonqueued-sender-com-spec{data-element=Value, init-value=CeOBCR_e_Current}, provided-interface=VeOBCR_e_ChrgrTrsfMethodReq
      VeOBCR_I_MaxAllowableCrntAC: nonqueued-sender-com-spec{data-element=Value, init-value=0}, provided-interface=VeOBCR_I_MaxAllowableCrntAC
      VeOBCR_U_MinAllowableBattVolt: nonqueued-sender-com-spec{data-element=Value, init-value=0}, provided-interface=VeOBCR_U_MinAllowableBattVolt
      VeOBCR_U_MaxAllowableBattVolt: nonqueued-sender-com-spec{data-element=Value, init-value=0}, provided-interface=VeOBCR_U_MaxAllowableBattVolt
      VeOBCR_I_MaxAllowableCrntBatt: nonqueued-sender-com-spec{data-element=Value, init-value=0}, provided-interface=VeOBCR_I_MaxAllowableCrntBatt
      VeOBCR_I_ChrgCrntReqDelta: nonqueued-sender-com-spec{data-element=Value, init-value=0}, provided-interface=VeOBCR_I_ChrgCrntReqDelta
      VeOBCR_U_ChrgVltReqDelta: nonqueued-sender-com-spec{data-element=Value, init-value=0}, provided-interface=VeOBCR_U_ChrgVltReqDelta
      VeOBCR_b_EnblChrg: nonqueued-sender-com-spec{data-element=Value, init-value=0}, provided-interface=VeOBCR_b_EnblChrg
      VeOBCR_b_CloseS2Cntctr: nonqueued-sender-com-spec{data-element=Value, init-value=0}, provided-interface=VeOBCR_b_CloseS2Cntctr
      VeOBCR_e_HVBattBalReq: nonqueued-sender-com-spec{data-element=Value, init-value=CeOBCR_e_NoRequest}, provided-interface=VeOBCR_e_HVBattBalReq
      VeOBCR_e_ChargingLevel: nonqueued-sender-com-spec{data-element=Value, init-value=CeOBCR_e_ChargingLvlDefault}, provided-interface=VeOBCR_e_ChargingLevel
      VeOBCR_e_ChargingSystemSts: nonqueued-sender-com-spec{data-element=Value, init-value=CeOBCR_e_NotCharging}, provided-interface=VeOBCR_e_ChargingSystemSts
      VeOBCR_t_EstTimeofChrg_Lv2: nonqueued-sender-com-spec{data-element=Value, init-value=0}, provided-interface=VeOBCR_t_EstTimeofChrg_Lv2
      VeOBCR_t_EstTimeofChrg_Lv1: nonqueued-sender-com-spec{data-element=Value, init-value=0}, provided-interface=VeOBCR_t_EstTimeofChrg_Lv1
      VeOBCR_b_RdyForShtDwn: nonqueued-sender-com-spec{data-element=Value, init-value=0}, provided-interface=VeOBCR_b_RdyForShtDwn
      VeOBCR_e_ChrgSysShtDwnFlt: nonqueued-sender-com-spec{data-element=Value, init-value=CeSRAR_e_NoFlt}, provided-interface=VeOBCR_e_ChrgSysShtDwnFlt
      VeOBCR_P_AvalPwrForThmr: nonqueued-sender-com-spec{data-element=Value, init-value=0}, provided-interface=VeOBCR_P_AvalPwrForThmr
      VeOBCR_Pct_TargetSOC: nonqueued-sender-com-spec{data-element=Value, init-value=0}, provided-interface=VeOBCR_Pct_TargetSOC
      VeOBCR_k_ChrgSysFault_Reason: nonqueued-sender-com-spec{data-element=Value, init-value=0}, provided-interface=VeOBCR_k_ChrgSysFault_Reason
      VeOBCR_b_EnableCANC: nonqueued-sender-com-spec{data-element=Value, init-value=0}, provided-interface=VeOBCR_b_EnableCANC
      VeOBCR_I_BattSideCurr: nonqueued-sender-com-spec{data-element=Value, init-value=0}, provided-interface=VeOBCR_I_BattSideCurr
      VeOBCR_b_ChargeReq_ToBPCM: nonqueued-sender-com-spec{data-element=Value, init-value=0}, provided-interface=VeOBCR_b_ChargeReq_ToBPCM
      VeOBCR_b_HMIR_MSG5: nonqueued-sender-com-spec{data-element=Value, init-value=0}, provided-interface=VeOBCR_b_HMIR_MSG5
      VeOBCR_b_HMIR_MSG6: nonqueued-sender-com-spec{data-element=Value, init-value=0}, provided-interface=VeOBCR_b_HMIR_MSG6
      VeOBCR_b_SecureConEst: nonqueued-sender-com-spec{data-element=Value, init-value=0}, provided-interface=VeOBCR_b_SecureConEst
      VeOBCR_e_ChrgPort_Req: nonqueued-sender-com-spec{data-element=Value, init-value=CeOBCR_e_PortNoRequest}, provided-interface=VeOBCR_e_ChrgPort_Req
      VeOBCR_b_HMIR_MSG8: nonqueued-sender-com-spec{data-element=Value, init-value=0}, provided-interface=VeOBCR_b_HMIR_MSG8
      VeOBCR_b_DVC_ChrgPort_Req: nonqueued-sender-com-spec{data-element=Value, init-value=0}, provided-interface=VeOBCR_b_DVC_ChrgPort_Req
      VeOBCR_b_Lock_Status: nonqueued-sender-com-spec{data-element=Value, init-value=0}, provided-interface=VeOBCR_b_Lock_Status
      VeOBCR_b_ChrgPort_BCM_Cmd: nonqueued-sender-com-spec{data-element=Value, init-value=0}, provided-interface=VeOBCR_b_ChrgPort_BCM_Cmd
      VeOBCR_b_SmartEvse_Dtctd: nonqueued-sender-com-spec{data-element=Value, init-value=0}, provided-interface=VeOBCR_b_SmartEvse_Dtctd
      VeOBCR_b_ValidPluginDetected: nonqueued-sender-com-spec{data-element=Value, init-value=0}, provided-interface=VeOBCR_b_ValidPluginDetected
      VeOBCR_b_RelockTimerActive: nonqueued-sender-com-spec{data-element=Value, init-value=0}, provided-interface=VeOBCR_b_RelockTimerActive
      VeOBCR_b_ChrgSysFaultBPCM: nonqueued-sender-com-spec{data-element=Value, init-value=0}, provided-interface=VeOBCR_b_ChrgSysFaultBPCM
      VeOBCR_b_PluggedIn: nonqueued-sender-com-spec{data-element=Value, init-value=0}, provided-interface=VeOBCR_b_PluggedIn
      VeOBCR_P_Est_PowerBudget: nonqueued-sender-com-spec{data-element=Value, init-value=0}, provided-interface=VeOBCR_P_Est_PowerBudget
      VeOBCR_b_HMIR_MSG13: nonqueued-sender-com-spec{data-element=Value, init-value=0}, provided-interface=VeOBCR_b_HMIR_MSG13
      VeOBCR_e_Service_Category: nonqueued-sender-com-spec{data-element=Value, init-value=0}, provided-interface=VeOBCR_e_Service_Category
      VeOBCR_e_SelEnrgyTxType: nonqueued-sender-com-spec{data-element=Value, init-value=0}, provided-interface=VeOBCR_e_SelEnrgyTxType
      VeOBCR_b_EVReady: nonqueued-sender-com-spec{data-element=Value, init-value=0}, provided-interface=VeOBCR_b_EVReady
      VeOBCR_e_HCP_EVErrorCode: nonqueued-sender-com-spec{data-element=Value, init-value=0}, provided-interface=VeOBCR_e_HCP_EVErrorCode
      VeOBCR_I_EVMax_I_Limit: nonqueued-sender-com-spec{data-element=Value, init-value=0}, provided-interface=VeOBCR_I_EVMax_I_Limit
      VeOBCR_P_EVMax_P_Limit: nonqueued-sender-com-spec{data-element=Value, init-value=0}, provided-interface=VeOBCR_P_EVMax_P_Limit
      VeOBCR_U_EVMax_V_Limit: nonqueued-sender-com-spec{data-element=Value, init-value=0}, provided-interface=VeOBCR_U_EVMax_V_Limit
      VeOBCR_E_EVEnergyCapacity: nonqueued-sender-com-spec{data-element=Value, init-value=0}, provided-interface=VeOBCR_E_EVEnergyCapacity
      VeOBCR_E_EVEnergyRequest: nonqueued-sender-com-spec{data-element=Value, init-value=0}, provided-interface=VeOBCR_E_EVEnergyRequest
      VeOBCR_b_DC_Isolation_Cmd: nonqueued-sender-com-spec{data-element=Value, init-value=0}, provided-interface=VeOBCR_b_DC_Isolation_Cmd
      VeOBCR_e_DC_CntctrCmd: nonqueued-sender-com-spec{data-element=Value, init-value=CeOBCR_e_DCCntctr_Open}, provided-interface=VeOBCR_e_DC_CntctrCmd
      VeOBCR_U_EV_DCTargetVolt: nonqueued-sender-com-spec{data-element=Value, init-value=0}, provided-interface=VeOBCR_U_EV_DCTargetVolt
      VeOBCR_b_WeldChkComplete: nonqueued-sender-com-spec{data-element=Value, init-value=0}, provided-interface=VeOBCR_b_WeldChkComplete
      VeOBCR_b_RdyToChrgSt: nonqueued-sender-com-spec{data-element=Value, init-value=0}, provided-interface=VeOBCR_b_RdyToChrgSt
      VeOBCR_b_ChargingComplete: nonqueued-sender-com-spec{data-element=Value, init-value=0}, provided-interface=VeOBCR_b_ChargingComplete
      VeOBCR_t_RemTimeToFullSOC: nonqueued-sender-com-spec{data-element=Value, init-value=0}, provided-interface=VeOBCR_t_RemTimeToFullSOC
      VeOBCR_K_SelectedServiceID: nonqueued-sender-com-spec{data-element=Value, init-value=0}, provided-interface=VeOBCR_K_SelectedServiceID
      VeOBCR_e_SelPayOptn: nonqueued-sender-com-spec{data-element=Value, init-value=CeOBCR_e_NoPaymentSel}, provided-interface=VeOBCR_e_SelPayOptn
      VeOBCR_b_HCP_SessionStpCmd: nonqueued-sender-com-spec{data-element=Value, init-value=0}, provided-interface=VeOBCR_b_HCP_SessionStpCmd
      VeOBCR_e_HCP_DC_Retry: nonqueued-sender-com-spec{data-element=Value, init-value=CeOBCR_e_No_Retry_Command}, provided-interface=VeOBCR_e_HCP_DC_Retry
      VeOBCR_e_ChargeType: nonqueued-sender-com-spec{data-element=Value, init-value=CeOBCR_e_AC}, provided-interface=VeOBCR_e_ChargeType
      VeOBCR_e_DCChrg_TestSts: nonqueued-sender-com-spec{data-element=Value, init-value=CeOBCR_e_DCChrg_TestSts_NotInit}, provided-interface=VeOBCR_e_DCChrg_TestSts
      VeOBCR_K_ChargingFailure{1..5}: nonqueued-sender-com-spec{data-element=Value, init-value=0}, provided-interface=VeOBCR_K_ChargingFailure{1..5}
      VeOBCR_b_ChrgPortReq_BSW: nonqueued-sender-com-spec{data-element=Value, init-value=0}, provided-interface=VeOBCR_b_ChrgPortReq_BSW
      VeOBCR_k_ChrgPortEnbl_BSW: nonqueued-sender-com-spec{data-element=Value, init-value=0}, provided-interface=VeOBCR_k_ChrgPortEnbl_BSW
      VeOBCR_t_EstTimeDCFastChrg_100: nonqueued-sender-com-spec{data-element=Value, init-value=0}, provided-interface=VeOBCR_t_EstTimeDCFastChrg_100
      VeOBCR_t_EstTimeDCFastChrg_80: nonqueued-sender-com-spec{data-element=Value, init-value=0}, provided-interface=VeOBCR_t_EstTimeDCFastChrg_80
      VeOBCR_I_MaxAllowedCurr: nonqueued-sender-com-spec{data-element=Value, init-value=0}, provided-interface=VeOBCR_I_MaxAllowedCurr
      VeOBCR_e_ChrgSysStat_SF: nonqueued-sender-com-spec{data-element=Value, init-value=CeOBCR_e_PowerUp}, provided-interface=VeOBCR_e_ChrgSysStat_SF
      VeOBCR_I_ChrgCurrEstSOC: nonqueued-sender-com-spec{data-element=Value, init-value=0}, provided-interface=VeOBCR_I_ChrgCurrEstSOC
      VeOBCR_b_DCChrgInitialization: nonqueued-sender-com-spec{data-element=Value, init-value=0}, provided-interface=VeOBCR_b_DCChrgInitialization
      VeOBCR_e_CellVolt_OOR: nonqueued-sender-com-spec{data-element=Value, init-value=CeOBCR_e_CellVoltStat_Normal}, provided-interface=VeOBCR_e_CellVolt_OOR
      VeOBCR_e_ChrgCurr_OOR: nonqueued-sender-com-spec{data-element=Value, init-value=CeOBCR_e_ChrgCurrStat_Normal}, provided-interface=VeOBCR_e_ChrgCurr_OOR
      VeOBCR_e_BattTemp_OOR: nonqueued-sender-com-spec{data-element=Value, init-value=CeOBCR_e_BattTempStat_Normal}, provided-interface=VeOBCR_e_BattTemp_OOR
      VeOBCR_e_SOC_OOR: nonqueued-sender-com-spec{data-element=Value, init-value=CeOBCR_e_BattSOCStat_Normal}, provided-interface=VeOBCR_e_SOC_OOR
      VeOBCR_b_CPIM_Error: nonqueued-sender-com-spec{data-element=Value, init-value=0}, provided-interface=VeOBCR_b_CPIM_Error
      VeOBCR_b_CPIM_OT: nonqueued-sender-com-spec{data-element=Value, init-value=0}, provided-interface=VeOBCR_b_CPIM_OT
      VeOBCR_Pct_BattFullSOC: nonqueued-sender-com-spec{data-element=Value, init-value=0}, provided-interface=VeOBCR_Pct_BattFullSOC
      VeOBCR_b_BattOverVolt: nonqueued-sender-com-spec{data-element=Value, init-value=0}, provided-interface=VeOBCR_b_BattOverVolt
      VeOBCR_b_BattUnderVolt: nonqueued-sender-com-spec{data-element=Value, init-value=0}, provided-interface=VeOBCR_b_BattUnderVolt
      VeOBCR_b_PluggedIn_EEPROM: nonqueued-sender-com-spec{data-element=Value, init-value=0}, provided-interface=VeOBCR_b_PluggedIn_EEPROM
      VeOBCR_e_BattPckVoltRchd_BST: nonqueued-sender-com-spec{data-element=Value, init-value=CeOBCR_e_BattPckVolt_NotReached}, provided-interface=VeOBCR_e_BattPckVoltRchd_BST
      VeOBCR_e_SOCRchd_BST: nonqueued-sender-com-spec{data-element=Value, init-value=CeOBCR_e_SOC_NotReached}, provided-interface=VeOBCR_e_SOCRchd_BST
      VeOBCR_b_DCGBTReadyToCharge: nonqueued-sender-com-spec{data-element=Value, init-value=0}, provided-interface=VeOBCR_b_DCGBTReadyToCharge
      VeOBCR_b_DCGBTEVChrgPermit: nonqueued-sender-com-spec{data-element=Value, init-value=0}, provided-interface=VeOBCR_b_DCGBTEVChrgPermit
      VeOBCR_e_MaxCellVoltRchd_BST: nonqueued-sender-com-spec{data-element=Value, init-value=CeOBCR_e_MaxCellVolt_NotReached}, provided-interface=VeOBCR_e_MaxCellVoltRchd_BST
      VeOBCR_P_PLS_PwrLev{1..5}: nonqueued-sender-com-spec{data-element=Value, init-value=0}, provided-interface=VeOBCR_P_PLS_PwrLev{1..5}
      VeOBCR_T_GBT_MaxBattTempAllwd: nonqueued-sender-com-spec{data-element=Value, init-value=0}, provided-interface=VeOBCR_T_GBT_MaxBattTempAllwd
      VeOBCR_e_GBT_ChrgCntrolMethod: nonqueued-sender-com-spec{data-element=Value, init-value=CeOBCR_e_ChrgMthd_Init}, provided-interface=VeOBCR_e_GBT_ChrgCntrolMethod
      VeOBCR_e_GBT_ChrgrInterrupt: nonqueued-sender-com-spec{data-element=Value, init-value=CeOBCR_e_NoChrgrInterrupt}, provided-interface=VeOBCR_e_GBT_ChrgrInterrupt
      VeOBCR_b_EnablePowerTransfer: nonqueued-sender-com-spec{data-element=Value, init-value=0}, provided-interface=VeOBCR_b_EnablePowerTransfer
      VeOBCR_b_SecureConnV2L: nonqueued-sender-com-spec{data-element=Value, init-value=0}, provided-interface=VeOBCR_b_SecureConnV2L
      VeOBCR_e_PwrLevSet: nonqueued-sender-com-spec{data-element=Value, init-value=CeOBCR_e_PwrLimReq_SNA}, provided-interface=VeOBCR_e_PwrLevSet
      VeOBCR_b_BPCM_Rdy: nonqueued-sender-com-spec{data-element=Value, init-value=0}, provided-interface=VeOBCR_b_BPCM_Rdy
      VeOBCR_e_SelectAppProtocol: nonqueued-sender-com-spec{data-element=Value, init-value=CeOBCR_e_DIN}, provided-interface=VeOBCR_e_SelectAppProtocol
      VeOBCR_b_SelectSecProtocol: nonqueued-sender-com-spec{data-element=Value, init-value=0}, provided-interface=VeOBCR_b_SelectSecProtocol
      VeOBCR_e_ChargeProgress: nonqueued-sender-com-spec{data-element=Value, init-value=CeOBCR_e_No_Request}, provided-interface=VeOBCR_e_ChargeProgress
      VeOBCR_e_DC_ChrgTypeCmd: nonqueued-sender-com-spec{data-element=Value, init-value=CeOBCR_e_DC_ChrgType_Null}, provided-interface=VeOBCR_e_DC_ChrgTypeCmd
      VeOBCR_e_ChargeportLock_Sts: nonqueued-sender-com-spec{data-element=Value, init-value=CeOBCR_e_PortLockSts_Default}, provided-interface=VeOBCR_e_ChargeportLock_Sts
      VeOBCR_b_RacePrepBattLvlSts: nonqueued-sender-com-spec{data-element=Value, init-value=0}, provided-interface=VeOBCR_b_RacePrepBattLvlSts
      VeOBCR_t_RemTimeToBulkSOC: nonqueued-sender-com-spec{data-element=Value, init-value=0}, provided-interface=VeOBCR_t_RemTimeToBulkSOC
      VeOBCR_Cnt_PlugIn_Reason: nonqueued-sender-com-spec{data-element=Value, init-value=0}, provided-interface=VeOBCR_Cnt_PlugIn_Reason
      VaOBCR_Cnt_PlugIn_Vector: nonqueued-sender-com-spec{data-element=Value, init-value=15 x 0}, provided-interface=VaOBCR_Cnt_PlugIn_Vector
      VeOBCR_b_ChrgrLOC: nonqueued-sender-com-spec{data-element=Value, init-value=0}, provided-interface=VeOBCR_b_ChrgrLOC
      VeOBCR_b_PlugInLock: nonqueued-sender-com-spec{data-element=Value, init-value=0}, provided-interface=VeOBCR_b_PlugInLock
      VaOBCR_b_NCR_Signals: nonqueued-sender-com-spec{data-element=Value, init-value=15 x 0}, provided-interface=VaOBCR_b_NCR_Signals
      VeOBCR_Cnt_InitChecks_Reason: nonqueued-sender-com-spec{data-element=Value, init-value=0}, provided-interface=VeOBCR_Cnt_InitChecks_Reason
      VeOBCR_b_EnableChargeDC: nonqueued-sender-com-spec{data-element=Value, init-value=0}, provided-interface=VeOBCR_b_EnableChargeDC
      VaOBCR_k_InitChecks_Vector: nonqueued-sender-com-spec{data-element=Value, init-value=7 x 0}, provided-interface=VaOBCR_k_InitChecks_Vector
      VeOBCR_Cnt_NCR: nonqueued-sender-com-spec{data-element=Value, init-value=0}, provided-interface=VeOBCR_Cnt_NCR
      VeOBCR_b_EnblDC_GBT: nonqueued-sender-com-spec{data-element=Value, init-value=0}, provided-interface=VeOBCR_b_EnblDC_GBT
      VeOBCR_b_EnblDsblProxPlg: nonqueued-sender-com-spec{data-element=Value, init-value=0}, provided-interface=VeOBCR_b_EnblDsblProxPlg
      VeOBCR_P_EVSEPwr: nonqueued-sender-com-spec{data-element=Value, init-value=0}, provided-interface=VeOBCR_P_EVSEPwr
      VeOBCR_P_PowertoBattery: nonqueued-sender-com-spec{data-element=Value, init-value=0}, provided-interface=VeOBCR_P_PowertoBattery
      VeOBCR_q_BatteryAmpHrCap: nonqueued-sender-com-spec{data-element=Value, init-value=0}, provided-interface=VeOBCR_q_BatteryAmpHrCap
      VeOBCR_P_ActChargePowerLim: nonqueued-sender-com-spec{data-element=Value, init-value=0}, provided-interface=VeOBCR_P_ActChargePowerLim
      VeOBCR_P_ActChargePower: nonqueued-sender-com-spec{data-element=Value, init-value=0}, provided-interface=VeOBCR_P_ActChargePower
      VeOBCR_b_ActChargePowerLimFA: nonqueued-sender-com-spec{data-element=Value, init-value=0}, provided-interface=VeOBCR_b_ActChargePowerLimFA
      VeOBCR_b_ActChargePowerFA: nonqueued-sender-com-spec{data-element=Value, init-value=0}, provided-interface=VeOBCR_b_ActChargePowerFA
      VeOBCR_b_PnCFailure: nonqueued-sender-com-spec{data-element=Value, init-value=0}, provided-interface=VeOBCR_b_PnCFailure
      VeOBCR_b_PnCRetryFail: nonqueued-sender-com-spec{data-element=Value, init-value=0}, provided-interface=VeOBCR_b_PnCRetryFail
      VeOBCR_e_Protocol_Priority{1..3}: nonqueued-sender-com-spec{data-element=Value, init-value=CeOBCR_e_No_Protocol}, provided-interface=VeOBCR_e_Protocol_Priority{1..3}
      VeOBCR_d_ServiceScope: nonqueued-sender-com-spec{data-element=Value, init-value=0}, provided-interface=VeOBCR_d_ServiceScope
      VeOBCR_k_MaxEntriesSASScheduleTuple: nonqueued-sender-com-spec{data-element=Value, init-value=0}, provided-interface=VeOBCR_k_MaxEntriesSASScheduleTuple
    9 x require port:
      EeOBCR_b_PluggedIn_Rx: nv-require-com-spec{init-value=0, variable=EeOBCR_b_PluggedIn}, required-interface=EeOBCR_b_PluggedIn
      EeOBCR_t_EstTimeofChrg_Lv1_Rx: nv-require-com-spec{init-value=0, variable=EeOBCR_t_EstTimeofChrg_Lv1}, required-interface=EeOBCR_t_EstTimeofChrg_Lv1
      EeOBCR_t_EstTimeofChrg_Lv2_Rx: nv-require-com-spec{init-value=0, variable=EeOBCR_t_EstTimeofChrg_Lv2}, required-interface=EeOBCR_t_EstTimeofChrg_Lv2
      EeOBCR_e_ChargingSystemSts_Rx: nv-require-com-spec{init-value=0, variable=EeOBCR_e_ChargingSystemSts}, required-interface=EeOBCR_e_ChargingSystemSts
      EeOBCR_e_ChargingLevel_Rx: nv-require-com-spec{init-value=0, variable=EeOBCR_e_ChargingLevel}, required-interface=EeOBCR_e_ChargingLevel
      NeOBCR_b_GoodConnEst_Rx: nv-require-com-spec{init-value=0, variable=NeOBCR_b_GoodConnEst}, required-interface=NeOBCR_b_GoodConnEst
      NeOBCR_b_Lvl1Latch_Rx: nv-require-com-spec{init-value=0, variable=NeOBCR_b_Lvl1Latch}, required-interface=NeOBCR_b_Lvl1Latch
      NeOBCR_b_Lvl2Latch_Rx: nv-require-com-spec{init-value=0, variable=NeOBCR_b_Lvl2Latch}, required-interface=NeOBCR_b_Lvl2Latch
      NeOBCR_b_SmartEvse_Detected_Rx: nv-require-com-spec{init-value=0, variable=NeOBCR_b_SmartEvse_Detected}, required-interface=NeOBCR_b_SmartEvse_Detected
    9 x provide port:
      EeOBCR_b_PluggedIn: nv-provide-com-spec{ram-block-init-value=0, variable=EeOBCR_b_PluggedIn}, provided-interface=EeOBCR_b_PluggedIn
      EeOBCR_t_EstTimeofChrg_Lv1: nv-provide-com-spec{ram-block-init-value=0, variable=EeOBCR_t_EstTimeofChrg_Lv1}, provided-interface=EeOBCR_t_EstTimeofChrg_Lv1
      EeOBCR_t_EstTimeofChrg_Lv2: nv-provide-com-spec{ram-block-init-value=0, variable=EeOBCR_t_EstTimeofChrg_Lv2}, provided-interface=EeOBCR_t_EstTimeofChrg_Lv2
      EeOBCR_e_ChargingSystemSts: nv-provide-com-spec{ram-block-init-value=0, variable=EeOBCR_e_ChargingSystemSts}, provided-interface=EeOBCR_e_ChargingSystemSts
      EeOBCR_e_ChargingLevel: nv-provide-com-spec{ram-block-init-value=0, variable=EeOBCR_e_ChargingLevel}, provided-interface=EeOBCR_e_ChargingLevel
      NeOBCR_b_GoodConnEst: nv-provide-com-spec{ram-block-init-value=0, variable=NeOBCR_b_GoodConnEst}, provided-interface=NeOBCR_b_GoodConnEst
      NeOBCR_b_Lvl1Latch: nv-provide-com-spec{ram-block-init-value=0, variable=NeOBCR_b_Lvl1Latch}, provided-interface=NeOBCR_b_Lvl1Latch
      NeOBCR_b_Lvl2Latch: nv-provide-com-spec{ram-block-init-value=0, variable=NeOBCR_b_Lvl2Latch}, provided-interface=NeOBCR_b_Lvl2Latch
      NeOBCR_b_SmartEvse_Detected: nv-provide-com-spec{ram-block-init-value=0, variable=NeOBCR_b_SmartEvse_Detected}, provided-interface=NeOBCR_b_SmartEvse_Detected
    35 x require port:
      HeOBCR_t_FnctRate: parameter-require-com-spec{init-value=HeOBCR_t_FnctRate_HeOBCR_t_FnctRate:0.025000000372529, parameter=HeOBCR_t_FnctRate}, required-interface=HeOBCR_t_FnctRate
      HeOBCR_t_dT: parameter-require-com-spec{init-value=HeOBCR_t_dT_HeOBCR_t_dT:0.025000000372529, parameter=HeOBCR_t_dT}, required-interface=HeOBCR_t_dT
      KeOBCR_Cnt_LatchUnplugInterupCnt: parameter-require-com-spec{init-value=KeOBCR_Cnt_LatchUnplugInterupCnt_KeOBCR_Cnt_LatchUnplugInterupCnt:2, parameter=KeOBCR_Cnt_LatchUnplugInterupCnt}, required-interface=KeOBCR_Cnt_LatchUnplugInterupCnt
      KeOBCR_I_MinJ1772ICA: parameter-require-com-spec{init-value=KeOBCR_I_MinJ1772ICA_KeOBCR_I_MinJ1772ICA:2, parameter=KeOBCR_I_MinJ1772ICA}, required-interface=KeOBCR_I_MinJ1772ICA
      KeOBCR_I_MinJ1772ICA1: parameter-require-com-spec{init-value=KeOBCR_I_MinJ1772ICA1_KeOBCR_I_MinJ1772ICA1:6, parameter=KeOBCR_I_MinJ1772ICA1}, required-interface=KeOBCR_I_MinJ1772ICA1
      KeOBCR_P_ThermalHys_Cal1: parameter-require-com-spec{init-value=KeOBCR_P_ThermalHys_Cal1_KeOBCR_P_ThermalHys_Cal1:100, parameter=KeOBCR_P_ThermalHys_Cal1}, required-interface=KeOBCR_P_ThermalHys_Cal1
      KeOBCR_P_ThermalHys_Cal2: parameter-require-com-spec{init-value=KeOBCR_P_ThermalHys_Cal2_KeOBCR_P_ThermalHys_Cal2:200, parameter=KeOBCR_P_ThermalHys_Cal2}, required-interface=KeOBCR_P_ThermalHys_Cal2
      KeOBCR_P_ThermalHys_Cal3: parameter-require-com-spec{init-value=KeOBCR_P_ThermalHys_Cal3_KeOBCR_P_ThermalHys_Cal3:200, parameter=KeOBCR_P_ThermalHys_Cal3}, required-interface=KeOBCR_P_ThermalHys_Cal3
      KeOBCR_U_MinValue2TrgrPPI: parameter-require-com-spec{init-value=KeOBCR_U_MinValue2TrgrPPI_KeOBCR_U_MinValue2TrgrPPI:50, parameter=KeOBCR_U_MinValue2TrgrPPI}, required-interface=KeOBCR_U_MinValue2TrgrPPI
      KeOBCR_k_ThermHysFactor: parameter-require-com-spec{init-value=KeOBCR_k_ThermHysFactor_KeOBCR_k_ThermHysFactor:0, parameter=KeOBCR_k_ThermHysFactor}, required-interface=KeOBCR_k_ThermHysFactor
      KeOBCR_t_BPCM_Ready: parameter-require-com-spec{init-value=KeOBCR_t_BPCM_Ready_KeOBCR_t_BPCM_Ready:15, parameter=KeOBCR_t_BPCM_Ready}, required-interface=KeOBCR_t_BPCM_Ready
      KeOBCR_t_BPCM_ReadyDelay: parameter-require-com-spec{init-value=KeOBCR_t_BPCM_ReadyDelay_KeOBCR_t_BPCM_ReadyDelay:0.100000001490116, parameter=KeOBCR_t_BPCM_ReadyDelay}, required-interface=KeOBCR_t_BPCM_ReadyDelay
      KeOBCR_t_ChargeCompleteDelay: parameter-require-com-spec{init-value=KeOBCR_t_ChargeCompleteDelay_KeOBCR_t_ChargeCompleteDelay:0.150000005960464, parameter=KeOBCR_t_ChargeCompleteDelay}, required-interface=KeOBCR_t_ChargeCompleteDelay
      KeOBCR_t_ChargePause: parameter-require-com-spec{init-value=KeOBCR_t_ChargePause_KeOBCR_t_ChargePause:0.200000002980232, parameter=KeOBCR_t_ChargePause}, required-interface=KeOBCR_t_ChargePause
      KeOBCR_t_CloseS2: parameter-require-com-spec{init-value=KeOBCR_t_CloseS2_KeOBCR_t_CloseS2:15, parameter=KeOBCR_t_CloseS2}, required-interface=KeOBCR_t_CloseS2
      KeOBCR_t_CloseS2Delay: parameter-require-com-spec{init-value=KeOBCR_t_CloseS2Delay_KeOBCR_t_CloseS2Delay:0.100000001490116, parameter=KeOBCR_t_CloseS2Delay}, required-interface=KeOBCR_t_CloseS2Delay
      KeOBCR_t_DCGBTInitWait: parameter-require-com-spec{init-value=60, parameter=KeOBCR_t_DCGBTInitWait}, required-interface=KeOBCR_t_DCGBTInitWait
      KeOBCR_t_DCInitWait: parameter-require-com-spec{init-value=20, parameter=KeOBCR_t_DCInitWait}, required-interface=KeOBCR_t_DCInitWait
      KeOBCR_t_DCMaxTime: parameter-require-com-spec{init-value=KeOBCR_t_DCMaxTime_KeOBCR_t_DCMaxTime:600, parameter=KeOBCR_t_DCMaxTime}, required-interface=KeOBCR_t_DCMaxTime
      KeOBCR_t_DbncTmPPI: parameter-require-com-spec{init-value=KeOBCR_t_DbncTmPPI_KeOBCR_t_DbncTmPPI:1, parameter=KeOBCR_t_DbncTmPPI}, required-interface=KeOBCR_t_DbncTmPPI
      KeOBCR_t_EnableChargeDelay: parameter-require-com-spec{init-value=KeOBCR_t_EnableChargeDelay_KeOBCR_t_EnableChargeDelay:0.150000005960464, parameter=KeOBCR_t_EnableChargeDelay}, required-interface=KeOBCR_t_EnableChargeDelay
      KeOBCR_t_OBCM_Charge: parameter-require-com-spec{init-value=KeOBCR_t_OBCM_Charge_KeOBCR_t_OBCM_Charge:15, parameter=KeOBCR_t_OBCM_Charge}, required-interface=KeOBCR_t_OBCM_Charge
      KeOBCR_t_OBCM_ChargeDelay: parameter-require-com-spec{init-value=KeOBCR_t_OBCM_ChargeDelay_KeOBCR_t_OBCM_ChargeDelay:0.100000001490116, parameter=KeOBCR_t_OBCM_ChargeDelay}, required-interface=KeOBCR_t_OBCM_ChargeDelay
      KeOBCR_t_OBCM_EnblCharge: parameter-require-com-spec{init-value=KeOBCR_t_OBCM_EnblCharge_KeOBCR_t_OBCM_EnblCharge:15, parameter=KeOBCR_t_OBCM_EnblCharge}, required-interface=KeOBCR_t_OBCM_EnblCharge
      KeOBCR_t_OBCM_EnblChargeDelay: parameter-require-com-spec{init-value=KeOBCR_t_OBCM_EnblChargeDelay_KeOBCR_t_OBCM_EnblChargeDelay:0.100000001490116, parameter=KeOBCR_t_OBCM_EnblChargeDelay}, required-interface=KeOBCR_t_OBCM_EnblChargeDelay
      KeOBCR_t_OBCM_Idle: parameter-require-com-spec{init-value=KeOBCR_t_OBCM_Idle_KeOBCR_t_OBCM_Idle:15, parameter=KeOBCR_t_OBCM_Idle}, required-interface=KeOBCR_t_OBCM_Idle
      KeOBCR_t_OBCM_IdleDelay: parameter-require-com-spec{init-value=KeOBCR_t_OBCM_IdleDelay_KeOBCR_t_OBCM_IdleDelay:0.100000001490116, parameter=KeOBCR_t_OBCM_IdleDelay}, required-interface=KeOBCR_t_OBCM_IdleDelay
      KeOBCR_t_PowerUp: parameter-require-com-spec{init-value=KeOBCR_t_PowerUp_KeOBCR_t_PowerUp:3, parameter=KeOBCR_t_PowerUp}, required-interface=KeOBCR_t_PowerUp
      KeOBCR_t_RetryDelay: parameter-require-com-spec{init-value=KeOBCR_t_RetryDelay_KeOBCR_t_RetryDelay:3, parameter=KeOBCR_t_RetryDelay}, required-interface=KeOBCR_t_RetryDelay
      KeOBCR_t_StateDbnc: parameter-require-com-spec{init-value=KeOBCR_t_StateDbnc_KeOBCR_t_StateDbnc:0.0500000007450581, parameter=KeOBCR_t_StateDbnc}, required-interface=KeOBCR_t_StateDbnc
      KeOBCR_t_StateShutDown: parameter-require-com-spec{init-value=KeOBCR_t_StateShutDown_KeOBCR_t_StateShutDown:1, parameter=KeOBCR_t_StateShutDown}, required-interface=KeOBCR_t_StateShutDown
      KeOBCR_t_StateTransTimer: parameter-require-com-spec{init-value=KeOBCR_t_StateTransTimer_KeOBCR_t_StateTransTimer:1, parameter=KeOBCR_t_StateTransTimer}, required-interface=KeOBCR_t_StateTransTimer
      KeOBCR_t_ThermHysDbnc: parameter-require-com-spec{init-value=KeOBCR_t_ThermHysDbnc_KeOBCR_t_ThermHysDbnc:50, parameter=KeOBCR_t_ThermHysDbnc}, required-interface=KeOBCR_t_ThermHysDbnc
      KeOBCR_t_UnplugDbnctime: parameter-require-com-spec{init-value=KeOBCR_t_UnplugDbnctime_KeOBCR_t_UnplugDbnctime:0.25, parameter=KeOBCR_t_UnplugDbnctime}, required-interface=KeOBCR_t_UnplugDbnctime
      KeOBCR_k_ChargingSts: parameter-require-com-spec{init-value=KeOBCR_k_ChargingSts_KeOBCR_k_ChargingSts:0, parameter=KeOBCR_k_ChargingSts}, required-interface=KeOBCR_k_ChargingSts
    behavior IB_OBCR: data-type-mapping=msADTtoIDTMapping, handle-termination-and-restart=NO-SUPPORT
      timing event Event_MedTED: start-on-event=OBCR_MedTED, period=0.02
      init event Event_OBCR_ac_Init: start-on-event=OBCR_ac_Init
      init event Event_PwrOn: start-on-event=OBCR_PwrOn
      init event Event_PwrOff: start-on-event=OBCR_PwrOff
      4 x runnable:
        OBCR_ac_Init
          data-send-points:
            33 x access:
              OUT_VeOBCR_e_ChrgrModeReq_Value: accessed-variable=VeOBCR_e_ChrgrModeReq.Value
              OUT_VeOBCR_e_ChrgrTrsfMethodReq_Value: accessed-variable=VeOBCR_e_ChrgrTrsfMethodReq.Value
              OUT_VeOBCR_e_HVBattBalReq_Value: accessed-variable=VeOBCR_e_HVBattBalReq.Value
              OUT_VeOBCR_e_ChargingLevel_Value: accessed-variable=VeOBCR_e_ChargingLevel.Value
              OUT_VeOBCR_e_ChargingSystemSts_Value: accessed-variable=VeOBCR_e_ChargingSystemSts.Value
              OUT_VeOBCR_e_ChrgSysShtDwnFlt_Value: accessed-variable=VeOBCR_e_ChrgSysShtDwnFlt.Value
              OUT_VeOBCR_e_ChrgPort_Req_Value: accessed-variable=VeOBCR_e_ChrgPort_Req.Value
              OUT_VeOBCR_e_DC_CntctrCmd_Value: accessed-variable=VeOBCR_e_DC_CntctrCmd.Value
              OUT_VeOBCR_e_SelPayOptn_Value: accessed-variable=VeOBCR_e_SelPayOptn.Value
              OUT_VeOBCR_e_HCP_DC_Retry_Value: accessed-variable=VeOBCR_e_HCP_DC_Retry.Value
              OUT_VeOBCR_e_ChargeType_Value: accessed-variable=VeOBCR_e_ChargeType.Value
              OUT_VeOBCR_e_DCChrg_TestSts_Value: accessed-variable=VeOBCR_e_DCChrg_TestSts.Value
              OUT_VeOBCR_e_ChrgSysStat_SF_Value: accessed-variable=VeOBCR_e_ChrgSysStat_SF.Value
              OUT_VeOBCR_e_CellVolt_OOR_Value: accessed-variable=VeOBCR_e_CellVolt_OOR.Value
              OUT_VeOBCR_e_ChrgCurr_OOR_Value: accessed-variable=VeOBCR_e_ChrgCurr_OOR.Value
              OUT_VeOBCR_e_BattTemp_OOR_Value: accessed-variable=VeOBCR_e_BattTemp_OOR.Value
              OUT_VeOBCR_e_SOC_OOR_Value: accessed-variable=VeOBCR_e_SOC_OOR.Value
              OUT_VeOBCR_e_BattPckVoltRchd_BST_Value: accessed-variable=VeOBCR_e_BattPckVoltRchd_BST.Value
              OUT_VeOBCR_e_SOCRchd_BST_Value: accessed-variable=VeOBCR_e_SOCRchd_BST.Value
              OUT_VeOBCR_e_MaxCellVoltRchd_BST_Value: accessed-variable=VeOBCR_e_MaxCellVoltRchd_BST.Value
              OUT_VeOBCR_e_GBT_ChrgCntrolMethod_Value: accessed-variable=VeOBCR_e_GBT_ChrgCntrolMethod.Value
              OUT_VeOBCR_e_GBT_ChrgrInterrupt_Value: accessed-variable=VeOBCR_e_GBT_ChrgrInterrupt.Value
              OUT_VeOBCR_e_PwrLevSet_Value: accessed-variable=VeOBCR_e_PwrLevSet.Value
              OUT_VeOBCR_e_SelectAppProtocol_Value: accessed-variable=VeOBCR_e_SelectAppProtocol.Value
              OUT_VeOBCR_e_ChargeProgress_Value: accessed-variable=VeOBCR_e_ChargeProgress.Value
              OUT_VeOBCR_e_DC_ChrgTypeCmd_Value: accessed-variable=VeOBCR_e_DC_ChrgTypeCmd.Value
              OUT_VeOBCR_e_ChargeportLock_Sts_Value: accessed-variable=VeOBCR_e_ChargeportLock_Sts.Value
              OUT_VaOBCR_Cnt_PlugIn_Vector_Value: accessed-variable=VaOBCR_Cnt_PlugIn_Vector.Value
              OUT_VaOBCR_b_NCR_Signals_Value: accessed-variable=VaOBCR_b_NCR_Signals.Value
              OUT_VaOBCR_k_InitChecks_Vector_Value: accessed-variable=VaOBCR_k_InitChecks_Vector.Value
              OUT_VeOBCR_e_Protocol_Priority{1..3}_Value: accessed-variable=VeOBCR_e_Protocol_Priority{1..3}.Value
        OBCR_PwrOn
          data-receive-point-by-arguments:
            9 x access:
              IN_EeOBCR_b_PluggedIn_Rx_EeOBCR_b_PluggedIn: accessed-variable=EeOBCR_b_PluggedIn_Rx.EeOBCR_b_PluggedIn
              IN_EeOBCR_e_ChargingLevel_Rx_EeOBCR_e_ChargingLevel: accessed-variable=EeOBCR_e_ChargingLevel_Rx.EeOBCR_e_ChargingLevel
              IN_EeOBCR_e_ChargingSystemSts_Rx_EeOBCR_e_ChargingSystemSts: accessed-variable=EeOBCR_e_ChargingSystemSts_Rx.EeOBCR_e_ChargingSystemSts
              IN_EeOBCR_t_EstTimeofChrg_Lv1_Rx_EeOBCR_t_EstTimeofChrg_Lv1: accessed-variable=EeOBCR_t_EstTimeofChrg_Lv1_Rx.EeOBCR_t_EstTimeofChrg_Lv1
              IN_EeOBCR_t_EstTimeofChrg_Lv2_Rx_EeOBCR_t_EstTimeofChrg_Lv2: accessed-variable=EeOBCR_t_EstTimeofChrg_Lv2_Rx.EeOBCR_t_EstTimeofChrg_Lv2
              IN_NeOBCR_b_GoodConnEst_Rx_NeOBCR_b_GoodConnEst: accessed-variable=NeOBCR_b_GoodConnEst_Rx.NeOBCR_b_GoodConnEst
              IN_NeOBCR_b_Lvl1Latch_Rx_NeOBCR_b_Lvl1Latch: accessed-variable=NeOBCR_b_Lvl1Latch_Rx.NeOBCR_b_Lvl1Latch
              IN_NeOBCR_b_Lvl2Latch_Rx_NeOBCR_b_Lvl2Latch: accessed-variable=NeOBCR_b_Lvl2Latch_Rx.NeOBCR_b_Lvl2Latch
              IN_NeOBCR_b_SmartEvse_Detected_Rx_NeOBCR_b_SmartEvse_Detected: accessed-variable=NeOBCR_b_SmartEvse_Detected_Rx.NeOBCR_b_SmartEvse_Detected
          data-send-points:
            133 x access:
              OUT_VeOBCR_b_PluggedIn_EEPROM_Value: accessed-variable=VeOBCR_b_PluggedIn_EEPROM.Value
              OUT_VeOBCR_b_ChrgSysFault_Value: accessed-variable=VeOBCR_b_ChrgSysFault.Value
              OUT_VeOBCR_e_ChargingSystemSts_Value: accessed-variable=VeOBCR_e_ChargingSystemSts.Value
              OUT_VeOBCR_t_EstTimeofChrg_Lv2_Value: accessed-variable=VeOBCR_t_EstTimeofChrg_Lv2.Value
              OUT_VeOBCR_t_EstTimeofChrg_Lv1_Value: accessed-variable=VeOBCR_t_EstTimeofChrg_Lv1.Value
              OUT_VeOBCR_e_ChargingLevel_Value: accessed-variable=VeOBCR_e_ChargingLevel.Value
              OUT_VeOBCR_e_ChrgrModeReq_Value: accessed-variable=VeOBCR_e_ChrgrModeReq.Value
              OUT_VeOBCR_e_ChrgrTrsfMethodReq_Value: accessed-variable=VeOBCR_e_ChrgrTrsfMethodReq.Value
              OUT_VeOBCR_I_MaxAllowableCrntAC_Value: accessed-variable=VeOBCR_I_MaxAllowableCrntAC.Value
              OUT_VeOBCR_U_MinAllowableBattVolt_Value: accessed-variable=VeOBCR_U_MinAllowableBattVolt.Value
              OUT_VeOBCR_U_MaxAllowableBattVolt_Value: accessed-variable=VeOBCR_U_MaxAllowableBattVolt.Value
              OUT_VeOBCR_I_MaxAllowableCrntBatt_Value: accessed-variable=VeOBCR_I_MaxAllowableCrntBatt.Value
              OUT_VeOBCR_I_ChrgCrntReqDelta_Value: accessed-variable=VeOBCR_I_ChrgCrntReqDelta.Value
              OUT_VeOBCR_U_ChrgVltReqDelta_Value: accessed-variable=VeOBCR_U_ChrgVltReqDelta.Value
              OUT_VeOBCR_b_EnblChrg_Value: accessed-variable=VeOBCR_b_EnblChrg.Value
              OUT_VeOBCR_b_CloseS2Cntctr_Value: accessed-variable=VeOBCR_b_CloseS2Cntctr.Value
              OUT_VeOBCR_e_HVBattBalReq_Value: accessed-variable=VeOBCR_e_HVBattBalReq.Value
              OUT_VeOBCR_b_RdyForShtDwn_Value: accessed-variable=VeOBCR_b_RdyForShtDwn.Value
              OUT_VeOBCR_e_ChrgSysShtDwnFlt_Value: accessed-variable=VeOBCR_e_ChrgSysShtDwnFlt.Value
              OUT_VeOBCR_P_AvalPwrForThmr_Value: accessed-variable=VeOBCR_P_AvalPwrForThmr.Value
              OUT_VeOBCR_Pct_TargetSOC_Value: accessed-variable=VeOBCR_Pct_TargetSOC.Value
              OUT_VeOBCR_k_ChrgSysFault_Reason_Value: accessed-variable=VeOBCR_k_ChrgSysFault_Reason.Value
              OUT_VeOBCR_b_EnableCANC_Value: accessed-variable=VeOBCR_b_EnableCANC.Value
              OUT_VeOBCR_I_BattSideCurr_Value: accessed-variable=VeOBCR_I_BattSideCurr.Value
              OUT_VeOBCR_b_ChargeReq_ToBPCM_Value: accessed-variable=VeOBCR_b_ChargeReq_ToBPCM.Value
              OUT_VeOBCR_b_HMIR_MSG5_Value: accessed-variable=VeOBCR_b_HMIR_MSG5.Value
              OUT_VeOBCR_b_HMIR_MSG6_Value: accessed-variable=VeOBCR_b_HMIR_MSG6.Value
              OUT_VeOBCR_b_SecureConEst_Value: accessed-variable=VeOBCR_b_SecureConEst.Value
              OUT_VeOBCR_e_ChrgPort_Req_Value: accessed-variable=VeOBCR_e_ChrgPort_Req.Value
              OUT_VeOBCR_b_HMIR_MSG8_Value: accessed-variable=VeOBCR_b_HMIR_MSG8.Value
              OUT_VeOBCR_b_DVC_ChrgPort_Req_Value: accessed-variable=VeOBCR_b_DVC_ChrgPort_Req.Value
              OUT_VeOBCR_b_Lock_Status_Value: accessed-variable=VeOBCR_b_Lock_Status.Value
              OUT_VeOBCR_b_ChrgPort_BCM_Cmd_Value: accessed-variable=VeOBCR_b_ChrgPort_BCM_Cmd.Value
              OUT_VeOBCR_b_SmartEvse_Dtctd_Value: accessed-variable=VeOBCR_b_SmartEvse_Dtctd.Value
              OUT_VeOBCR_b_ValidPluginDetected_Value: accessed-variable=VeOBCR_b_ValidPluginDetected.Value
              OUT_VeOBCR_b_RelockTimerActive_Value: accessed-variable=VeOBCR_b_RelockTimerActive.Value
              OUT_VeOBCR_b_ChrgSysFaultBPCM_Value: accessed-variable=VeOBCR_b_ChrgSysFaultBPCM.Value
              OUT_VeOBCR_b_PluggedIn_Value: accessed-variable=VeOBCR_b_PluggedIn.Value
              OUT_VeOBCR_P_Est_PowerBudget_Value: accessed-variable=VeOBCR_P_Est_PowerBudget.Value
              OUT_VeOBCR_b_HMIR_MSG13_Value: accessed-variable=VeOBCR_b_HMIR_MSG13.Value
              OUT_VeOBCR_e_Service_Category_Value: accessed-variable=VeOBCR_e_Service_Category.Value
              OUT_VeOBCR_e_SelEnrgyTxType_Value: accessed-variable=VeOBCR_e_SelEnrgyTxType.Value
              OUT_VeOBCR_b_EVReady_Value: accessed-variable=VeOBCR_b_EVReady.Value
              OUT_VeOBCR_e_HCP_EVErrorCode_Value: accessed-variable=VeOBCR_e_HCP_EVErrorCode.Value
              OUT_VeOBCR_I_EVMax_I_Limit_Value: accessed-variable=VeOBCR_I_EVMax_I_Limit.Value
              OUT_VeOBCR_P_EVMax_P_Limit_Value: accessed-variable=VeOBCR_P_EVMax_P_Limit.Value
              OUT_VeOBCR_U_EVMax_V_Limit_Value: accessed-variable=VeOBCR_U_EVMax_V_Limit.Value
              OUT_VeOBCR_E_EVEnergyCapacity_Value: accessed-variable=VeOBCR_E_EVEnergyCapacity.Value
              OUT_VeOBCR_E_EVEnergyRequest_Value: accessed-variable=VeOBCR_E_EVEnergyRequest.Value
              OUT_VeOBCR_b_DC_Isolation_Cmd_Value: accessed-variable=VeOBCR_b_DC_Isolation_Cmd.Value
              OUT_VeOBCR_e_DC_CntctrCmd_Value: accessed-variable=VeOBCR_e_DC_CntctrCmd.Value
              OUT_VeOBCR_U_EV_DCTargetVolt_Value: accessed-variable=VeOBCR_U_EV_DCTargetVolt.Value
              OUT_VeOBCR_b_WeldChkComplete_Value: accessed-variable=VeOBCR_b_WeldChkComplete.Value
              OUT_VeOBCR_b_RdyToChrgSt_Value: accessed-variable=VeOBCR_b_RdyToChrgSt.Value
              OUT_VeOBCR_b_ChargingComplete_Value: accessed-variable=VeOBCR_b_ChargingComplete.Value
              OUT_VeOBCR_t_RemTimeToFullSOC_Value: accessed-variable=VeOBCR_t_RemTimeToFullSOC.Value
              OUT_VeOBCR_K_SelectedServiceID_Value: accessed-variable=VeOBCR_K_SelectedServiceID.Value
              OUT_VeOBCR_e_SelPayOptn_Value: accessed-variable=VeOBCR_e_SelPayOptn.Value
              OUT_VeOBCR_b_HCP_SessionStpCmd_Value: accessed-variable=VeOBCR_b_HCP_SessionStpCmd.Value
              OUT_VeOBCR_e_HCP_DC_Retry_Value: accessed-variable=VeOBCR_e_HCP_DC_Retry.Value
              OUT_VeOBCR_e_ChargeType_Value: accessed-variable=VeOBCR_e_ChargeType.Value
              OUT_VeOBCR_e_DCChrg_TestSts_Value: accessed-variable=VeOBCR_e_DCChrg_TestSts.Value
              OUT_VeOBCR_K_ChargingFailure{1..5}_Value: accessed-variable=VeOBCR_K_ChargingFailure{1..5}.Value
              OUT_VeOBCR_b_ChrgPortReq_BSW_Value: accessed-variable=VeOBCR_b_ChrgPortReq_BSW.Value
              OUT_VeOBCR_k_ChrgPortEnbl_BSW_Value: accessed-variable=VeOBCR_k_ChrgPortEnbl_BSW.Value
              OUT_VeOBCR_t_EstTimeDCFastChrg_100_Value: accessed-variable=VeOBCR_t_EstTimeDCFastChrg_100.Value
              OUT_VeOBCR_t_EstTimeDCFastChrg_80_Value: accessed-variable=VeOBCR_t_EstTimeDCFastChrg_80.Value
              OUT_VeOBCR_I_MaxAllowedCurr_Value: accessed-variable=VeOBCR_I_MaxAllowedCurr.Value
              OUT_VeOBCR_e_ChrgSysStat_SF_Value: accessed-variable=VeOBCR_e_ChrgSysStat_SF.Value
              OUT_VeOBCR_I_ChrgCurrEstSOC_Value: accessed-variable=VeOBCR_I_ChrgCurrEstSOC.Value
              OUT_VeOBCR_b_DCChrgInitialization_Value: accessed-variable=VeOBCR_b_DCChrgInitialization.Value
              OUT_VeOBCR_e_CellVolt_OOR_Value: accessed-variable=VeOBCR_e_CellVolt_OOR.Value
              OUT_VeOBCR_e_ChrgCurr_OOR_Value: accessed-variable=VeOBCR_e_ChrgCurr_OOR.Value
              OUT_VeOBCR_e_BattTemp_OOR_Value: accessed-variable=VeOBCR_e_BattTemp_OOR.Value
              OUT_VeOBCR_e_SOC_OOR_Value: accessed-variable=VeOBCR_e_SOC_OOR.Value
              OUT_VeOBCR_b_CPIM_Error_Value: accessed-variable=VeOBCR_b_CPIM_Error.Value
              OUT_VeOBCR_b_CPIM_OT_Value: accessed-variable=VeOBCR_b_CPIM_OT.Value
              OUT_VeOBCR_Pct_BattFullSOC_Value: accessed-variable=VeOBCR_Pct_BattFullSOC.Value
              OUT_VeOBCR_b_BattOverVolt_Value: accessed-variable=VeOBCR_b_BattOverVolt.Value
              OUT_VeOBCR_b_BattUnderVolt_Value: accessed-variable=VeOBCR_b_BattUnderVolt.Value
              OUT_VeOBCR_e_BattPckVoltRchd_BST_Value: accessed-variable=VeOBCR_e_BattPckVoltRchd_BST.Value
              OUT_VeOBCR_e_SOCRchd_BST_Value: accessed-variable=VeOBCR_e_SOCRchd_BST.Value
              OUT_VeOBCR_b_DCGBTReadyToCharge_Value: accessed-variable=VeOBCR_b_DCGBTReadyToCharge.Value
              OUT_VeOBCR_b_DCGBTEVChrgPermit_Value: accessed-variable=VeOBCR_b_DCGBTEVChrgPermit.Value
              OUT_VeOBCR_e_MaxCellVoltRchd_BST_Value: accessed-variable=VeOBCR_e_MaxCellVoltRchd_BST.Value
              OUT_VeOBCR_P_PLS_PwrLev{1..5}_Value: accessed-variable=VeOBCR_P_PLS_PwrLev{1..5}.Value
              OUT_VeOBCR_T_GBT_MaxBattTempAllwd_Value: accessed-variable=VeOBCR_T_GBT_MaxBattTempAllwd.Value
              OUT_VeOBCR_e_GBT_ChrgCntrolMethod_Value: accessed-variable=VeOBCR_e_GBT_ChrgCntrolMethod.Value
              OUT_VeOBCR_e_GBT_ChrgrInterrupt_Value: accessed-variable=VeOBCR_e_GBT_ChrgrInterrupt.Value
              OUT_VeOBCR_b_EnablePowerTransfer_Value: accessed-variable=VeOBCR_b_EnablePowerTransfer.Value
              OUT_VeOBCR_b_SecureConnV2L_Value: accessed-variable=VeOBCR_b_SecureConnV2L.Value
              OUT_VeOBCR_e_PwrLevSet_Value: accessed-variable=VeOBCR_e_PwrLevSet.Value
              OUT_VeOBCR_b_BPCM_Rdy_Value: accessed-variable=VeOBCR_b_BPCM_Rdy.Value
              OUT_VeOBCR_e_SelectAppProtocol_Value: accessed-variable=VeOBCR_e_SelectAppProtocol.Value
              OUT_VeOBCR_b_SelectSecProtocol_Value: accessed-variable=VeOBCR_b_SelectSecProtocol.Value
              OUT_VeOBCR_e_ChargeProgress_Value: accessed-variable=VeOBCR_e_ChargeProgress.Value
              OUT_VeOBCR_e_DC_ChrgTypeCmd_Value: accessed-variable=VeOBCR_e_DC_ChrgTypeCmd.Value
              OUT_VeOBCR_e_ChargeportLock_Sts_Value: accessed-variable=VeOBCR_e_ChargeportLock_Sts.Value
              OUT_VeOBCR_b_RacePrepBattLvlSts_Value: accessed-variable=VeOBCR_b_RacePrepBattLvlSts.Value
              OUT_VeOBCR_t_RemTimeToBulkSOC_Value: accessed-variable=VeOBCR_t_RemTimeToBulkSOC.Value
              OUT_VeOBCR_Cnt_PlugIn_Reason_Value: accessed-variable=VeOBCR_Cnt_PlugIn_Reason.Value
              OUT_VaOBCR_Cnt_PlugIn_Vector_Value: accessed-variable=VaOBCR_Cnt_PlugIn_Vector.Value
              OUT_VeOBCR_b_ChrgrLOC_Value: accessed-variable=VeOBCR_b_ChrgrLOC.Value
              OUT_VeOBCR_b_PlugInLock_Value: accessed-variable=VeOBCR_b_PlugInLock.Value
              OUT_VaOBCR_b_NCR_Signals_Value: accessed-variable=VaOBCR_b_NCR_Signals.Value
              OUT_VeOBCR_Cnt_InitChecks_Reason_Value: accessed-variable=VeOBCR_Cnt_InitChecks_Reason.Value
              OUT_VeOBCR_b_EnableChargeDC_Value: accessed-variable=VeOBCR_b_EnableChargeDC.Value
              OUT_VaOBCR_k_InitChecks_Vector_Value: accessed-variable=VaOBCR_k_InitChecks_Vector.Value
              OUT_VeOBCR_Cnt_NCR_Value: accessed-variable=VeOBCR_Cnt_NCR.Value
              OUT_VeOBCR_b_EnblDC_GBT_Value: accessed-variable=VeOBCR_b_EnblDC_GBT.Value
              OUT_VeOBCR_b_EnblDsblProxPlg_Value: accessed-variable=VeOBCR_b_EnblDsblProxPlg.Value
              OUT_VeOBCR_P_EVSEPwr_Value: accessed-variable=VeOBCR_P_EVSEPwr.Value
              OUT_VeOBCR_P_PowertoBattery_Value: accessed-variable=VeOBCR_P_PowertoBattery.Value
              OUT_VeOBCR_q_BatteryAmpHrCap_Value: accessed-variable=VeOBCR_q_BatteryAmpHrCap.Value
              OUT_VeOBCR_P_ActChargePowerLim_Value: accessed-variable=VeOBCR_P_ActChargePowerLim.Value
              OUT_VeOBCR_P_ActChargePower_Value: accessed-variable=VeOBCR_P_ActChargePower.Value
              OUT_VeOBCR_b_ActChargePowerLimFA_Value: accessed-variable=VeOBCR_b_ActChargePowerLimFA.Value
              OUT_VeOBCR_b_ActChargePowerFA_Value: accessed-variable=VeOBCR_b_ActChargePowerFA.Value
              OUT_VeOBCR_b_PnCFailure_Value: accessed-variable=VeOBCR_b_PnCFailure.Value
              OUT_VeOBCR_b_PnCRetryFail_Value: accessed-variable=VeOBCR_b_PnCRetryFail.Value
              OUT_VeOBCR_e_Protocol_Priority{1..3}_Value: accessed-variable=VeOBCR_e_Protocol_Priority{1..3}.Value
              OUT_VeOBCR_k_MaxEntriesSASScheduleTuple_Value: accessed-variable=VeOBCR_k_MaxEntriesSASScheduleTuple.Value
              OUT_VeOBCR_d_ServiceScope_Value: accessed-variable=VeOBCR_d_ServiceScope.Value
        OBCR_MedTED
          data-receive-point-by-arguments:
            176 x access:
              IN_VeBPCR_Pct_HV_BatPackSOC_Arb_Value: accessed-variable=VeBPCR_Pct_HV_BatPackSOC_Arb.Value, variation-point={short-label=vpIN_VeBPCR_Pct_HV_BatPackSOC_Arb_Value, sw-syscond=1}
              IN_VeBPCR_T_BatModTmp_Value: accessed-variable=VeBPCR_T_BatModTmp.Value, variation-point={short-label=vpIN_VeBPCR_T_BatModTmp_Value, sw-syscond=1}
              IN_VeBPCR_b_HVBat_DC_CntctrOpn_Value: accessed-variable=VeBPCR_b_HVBat_DC_CntctrOpn.Value
              IN_VeBPCR_b_HVBat_DC_CntctrReq_Value: accessed-variable=VeBPCR_b_HVBat_DC_CntctrReq.Value
              IN_VeBPCR_b_HV_AuxLoadOffReq_Value: accessed-variable=VeBPCR_b_HV_AuxLoadOffReq.Value
              IN_VeBPCR_b_HV_BatCntctrOpenPending_Value: accessed-variable=VeBPCR_b_HV_BatCntctrOpenPending.Value
              IN_VeBPCR_b_HV_BatCntctrOpenReq_Value: accessed-variable=VeBPCR_b_HV_BatCntctrOpenReq.Value
              IN_VeBPCR_e_ChargingStat_BPCM_Value: accessed-variable=VeBPCR_e_ChargingStat_BPCM.Value
              IN_VeBPCR_e_HVTracBatCntctrConfig_Value: accessed-variable=VeBPCR_e_HVTracBatCntctrConfig.Value
              IN_VeBPCR_e_HV_BatCntctrStat_Value: accessed-variable=VeBPCR_e_HV_BatCntctrStat.Value, variation-point={short-label=vpIN_VeBPCR_e_HV_BatCntctrStat_Value, sw-syscond=1}
              IN_VeBPCR_q_FullAmpHrCap_Value: accessed-variable=VeBPCR_q_FullAmpHrCap.Value
              IN_VeCCCR_I_BattCommandedCurr_Value: accessed-variable=VeCCCR_I_BattCommandedCurr.Value, variation-point={short-label=vpIN_VeCCCR_I_BattCommandedCurr_Value, sw-syscond=1}
              IN_VeCCCR_I_ChrgCrntReqDelta_Value: accessed-variable=VeCCCR_I_ChrgCrntReqDelta.Value
              IN_VeCCCR_I_ChrgTypeHWLim_Value: accessed-variable=VeCCCR_I_ChrgTypeHWLim.Value, variation-point={short-label=vpIN_VeCCCR_I_ChrgTypeHWLim_Value, sw-syscond=1}
              IN_VeCCCR_I_HWCurrentBound_Value: accessed-variable=VeCCCR_I_HWCurrentBound.Value, variation-point={short-label=vpIN_VeCCCR_I_HWCurrentBound_Value, sw-syscond=1}
              IN_VeCCCR_I_MaxAllowedCurr_Value: accessed-variable=VeCCCR_I_MaxAllowedCurr.Value
              IN_VeCCCR_I_PLS_ReducedCurr_Value: accessed-variable=VeCCCR_I_PLS_ReducedCurr.Value, variation-point={short-label=vpIN_VeCCCR_I_PLS_ReducedCurr_Value, sw-syscond=1}
              IN_VeCCCR_P_PLS_PwrLev{1..5}_Value: accessed-variable=VeCCCR_P_PLS_PwrLev{1..5}.Value
              IN_VeCCCR_b_ChrgCmplteCondtnMet_Value: accessed-variable=VeCCCR_b_ChrgCmplteCondtnMet.Value, variation-point={short-label=vpIN_VeCCCR_b_ChrgCmplteCondtnMet_Value, sw-syscond=1}
              IN_VeCCCR_b_PwrLevActive_Value: accessed-variable=VeCCCR_b_PwrLevActive.Value, variation-point={short-label=vpIN_VeCCCR_b_PwrLevActive_Value, sw-syscond=1}
              IN_VeCCCR_b_SOC_LvlSet_80_Value: accessed-variable=VeCCCR_b_SOC_LvlSet_80.Value
              IN_VeCCCR_e_BattPckVoltRchd_BST_Value: accessed-variable=VeCCCR_e_BattPckVoltRchd_BST.Value
              IN_VeCCCR_e_HVBattBalReq_Value: accessed-variable=VeCCCR_e_HVBattBalReq.Value
              IN_VeCCCR_e_MaxCellVoltRchd_BST_Value: accessed-variable=VeCCCR_e_MaxCellVoltRchd_BST.Value
              IN_VeCCCR_e_PwrLevSet_Value: accessed-variable=VeCCCR_e_PwrLevSet.Value
              IN_VeCCCR_e_SOCRchd_BST_Value: accessed-variable=VeCCCR_e_SOCRchd_BST.Value
              IN_VeCHFR_I_BattSideCurr_Value: accessed-variable=VeCHFR_I_BattSideCurr.Value
              IN_VeCHFR_K_ChargingFailure{1..5}_Value: accessed-variable=VeCHFR_K_ChargingFailure{1..5}.Value
              IN_VeCHFR_U_ChrgVltReqDelta_Value: accessed-variable=VeCHFR_U_ChrgVltReqDelta.Value
              IN_VeCHFR_b_ACPrnt_S2Open_Value: accessed-variable=VeCHFR_b_ACPrnt_S2Open.Value, variation-point={short-label=vpIN_VeCHFR_b_ACPrnt_S2Open_Value, sw-syscond=1}
              IN_VeCHFR_b_CANC_WU_NCV_Value: accessed-variable=VeCHFR_b_CANC_WU_NCV.Value, variation-point={short-label=vpIN_VeCHFR_b_CANC_WU_NCV_Value, sw-syscond=1}
              IN_VeCHFR_b_ChargeReq_ToBPCM_Value: accessed-variable=VeCHFR_b_ChargeReq_ToBPCM.Value
              IN_VeCHFR_b_ChargingFault_Value: accessed-variable=VeCHFR_b_ChargingFault.Value, variation-point={short-label=vpIN_VeCHFR_b_ChargingFault_Value, sw-syscond=1}
              IN_VeCHFR_b_ChrgSysFault_Value: accessed-variable=VeCHFR_b_ChrgSysFault.Value
              IN_VeCHFR_b_ChrgSysFaultBPCM_Value: accessed-variable=VeCHFR_b_ChrgSysFaultBPCM.Value
              IN_VeCHFR_b_GiveUp_Value: accessed-variable=VeCHFR_b_GiveUp.Value, variation-point={short-label=vpIN_VeCHFR_b_GiveUp_Value, sw-syscond=1}
              IN_VeCHFR_b_HMIR_MSG5_Value: accessed-variable=VeCHFR_b_HMIR_MSG5.Value
              IN_VeCHFR_b_HMIR_MSG6_Value: accessed-variable=VeCHFR_b_HMIR_MSG6.Value
              IN_VeCHFR_b_HMIR_MSG8_Value: accessed-variable=VeCHFR_b_HMIR_MSG8.Value
              IN_VeCHFR_b_Reset_Charging_Value: accessed-variable=VeCHFR_b_Reset_Charging.Value, variation-point={short-label=vpIN_VeCHFR_b_Reset_Charging_Value, sw-syscond=1}
              IN_VeCHFR_k_ChrgSysFault_Reason_Value: accessed-variable=VeCHFR_k_ChrgSysFault_Reason.Value
              IN_VeCHFR_v_ModifiedVehSpeed_Value: accessed-variable=VeCHFR_v_ModifiedVehSpeed.Value, variation-point={short-label=vpIN_VeCHFR_v_ModifiedVehSpeed_Value, sw-syscond=1}
              IN_VeCITR_b_ChrgPort_BCM_Cmd_Out_Value: accessed-variable=VeCITR_b_ChrgPort_BCM_Cmd_Out.Value, variation-point={short-label=vpIN_VeCITR_b_ChrgPort_BCM_Cmd_Out_Value, sw-syscond=1}
              IN_VeCPLR_b_ChrgPortReq_BSW_Value: accessed-variable=VeCPLR_b_ChrgPortReq_BSW.Value
              IN_VeCPLR_b_DVC_ChrgPort_Req_Value: accessed-variable=VeCPLR_b_DVC_ChrgPort_Req.Value
              IN_VeCPLR_b_HMIR_MSG13_Value: accessed-variable=VeCPLR_b_HMIR_MSG13.Value
              IN_VeCPLR_b_InternalLockReq_Value: accessed-variable=VeCPLR_b_InternalLockReq.Value, variation-point={short-label=vpIN_VeCPLR_b_InternalLockReq_Value, sw-syscond=1}
              IN_VeCPLR_b_Lock_Status_Value: accessed-variable=VeCPLR_b_Lock_Status.Value
              IN_VeCPLR_b_RelockTimerActive_Value: accessed-variable=VeCPLR_b_RelockTimerActive.Value
              IN_VeCPLR_e_ChargePortLock_Sts_Value: accessed-variable=VeCPLR_e_ChargePortLock_Sts.Value
              IN_VeCPLR_e_ChrgPort_Req_Value: accessed-variable=VeCPLR_e_ChrgPort_Req.Value
              IN_VeCPLR_k_ChrgPortEnbl_BSW_Value: accessed-variable=VeCPLR_k_ChrgPortEnbl_BSW.Value
              IN_VeDCCR_E_EVEnergyCapacity_Value: accessed-variable=VeDCCR_E_EVEnergyCapacity.Value
              IN_VeDCCR_I_EVMax_I_Limit_Value: accessed-variable=VeDCCR_I_EVMax_I_Limit.Value
              IN_VeDCCR_K_SelectedServiceID_Value: accessed-variable=VeDCCR_K_SelectedServiceID.Value
              IN_VeDCCR_P_EVMax_P_Limit_Value: accessed-variable=VeDCCR_P_EVMax_P_Limit.Value
              IN_VeDCCR_Pct_BattFullSOC_Value: accessed-variable=VeDCCR_Pct_BattFullSOC.Value
              IN_VeDCCR_T_GBT_MaxBattTempAllwd_Value: accessed-variable=VeDCCR_T_GBT_MaxBattTempAllwd.Value
              IN_VeDCCR_U_EVMax_V_Limit_Value: accessed-variable=VeDCCR_U_EVMax_V_Limit.Value
              IN_VeDCCR_U_EV_DCTargetVolt_Value: accessed-variable=VeDCCR_U_EV_DCTargetVolt.Value
              IN_VeDCCR_b_BattOverVolt_Value: accessed-variable=VeDCCR_b_BattOverVolt.Value
              IN_VeDCCR_b_BattUnderVolt_Value: accessed-variable=VeDCCR_b_BattUnderVolt.Value
              IN_VeDCCR_b_CPIM_Error_Value: accessed-variable=VeDCCR_b_CPIM_Error.Value
              IN_VeDCCR_b_CPIM_OT_Value: accessed-variable=VeDCCR_b_CPIM_OT.Value
              IN_VeDCCR_b_DCChrgInitialization_Value: accessed-variable=VeDCCR_b_DCChrgInitialization.Value
              IN_VeDCCR_b_DCGBTEVChrgPermit_Value: accessed-variable=VeDCCR_b_DCGBTEVChrgPermit.Value
              IN_VeDCCR_b_DCGBTReadyToCharge_Value: accessed-variable=VeDCCR_b_DCGBTReadyToCharge.Value
              IN_VeDCCR_b_DC_Isolation_Cmd_Value: accessed-variable=VeDCCR_b_DC_Isolation_Cmd.Value
              IN_VeDCCR_b_EVReady_Value: accessed-variable=VeDCCR_b_EVReady.Value
              IN_VeDCCR_b_HCP_SessionStpCmd_Value: accessed-variable=VeDCCR_b_HCP_SessionStpCmd.Value
              IN_VeDCCR_b_J1772_S2_Close_DC_SF_Value: accessed-variable=VeDCCR_b_J1772_S2_Close_DC_SF.Value, variation-point={short-label=vpIN_VeDCCR_b_J1772_S2_Close_DC_SF_Value, sw-syscond=1}
              IN_VeDCCR_b_PnCFailure_Value: accessed-variable=VeDCCR_b_PnCFailure.Value
              IN_VeDCCR_b_PnCRetryFail_Value: accessed-variable=VeDCCR_b_PnCRetryFail.Value
              IN_VeDCCR_b_RdyToChrgSt_Value: accessed-variable=VeDCCR_b_RdyToChrgSt.Value
              IN_VeDCCR_b_SelectSecProtocol_Value: accessed-variable=VeDCCR_b_SelectSecProtocol.Value
              IN_VeDCCR_b_V2GPilotEnable_Value: accessed-variable=VeDCCR_b_V2GPilotEnable.Value, variation-point={short-label=vpIN_VeDCCR_b_V2GPilotEnable_Value, sw-syscond=1}
              IN_VeDCCR_b_WeldChkComplete_Value: accessed-variable=VeDCCR_b_WeldChkComplete.Value
              IN_VeDCCR_e_BattTemp_OOR_Value: accessed-variable=VeDCCR_e_BattTemp_OOR.Value
              IN_VeDCCR_e_CellVolt_OOR_Value: accessed-variable=VeDCCR_e_CellVolt_OOR.Value
              IN_VeDCCR_e_ChargeProgress_Value: accessed-variable=VeDCCR_e_ChargeProgress.Value
              IN_VeDCCR_e_ChrgCurr_OOR_Value: accessed-variable=VeDCCR_e_ChrgCurr_OOR.Value
              IN_VeDCCR_e_DCChrgSysStat_SF_Value: accessed-variable=VeDCCR_e_DCChrgSysStat_SF.Value, variation-point={short-label=vpIN_VeDCCR_e_DCChrgSysStat_SF_Value, sw-syscond=1}
              IN_VeDCCR_e_DCChrg_TestSts_Value: accessed-variable=VeDCCR_e_DCChrg_TestSts.Value
              IN_VeDCCR_e_DCGBTChrgSysStat_Value: accessed-variable=VeDCCR_e_DCGBTChrgSysStat.Value, variation-point={short-label=vpIN_VeDCCR_e_DCGBTChrgSysStat_Value, sw-syscond=1}
              IN_VeDCCR_e_DC_ChrgTypeCmd_Value: accessed-variable=VeDCCR_e_DC_ChrgTypeCmd.Value
              IN_VeDCCR_e_DC_CntctrCmd_Value: accessed-variable=VeDCCR_e_DC_CntctrCmd.Value
              IN_VeDCCR_e_GBT_ChrgCntrolMethod_Value: accessed-variable=VeDCCR_e_GBT_ChrgCntrolMethod.Value
              IN_VeDCCR_e_GBT_ChrgrInterrupt_Value: accessed-variable=VeDCCR_e_GBT_ChrgrInterrupt.Value
              IN_VeDCCR_e_HCP_EVErrorCode_Value: accessed-variable=VeDCCR_e_HCP_EVErrorCode.Value
              IN_VeDCCR_e_Protocol_Priority{1..3}_Value: accessed-variable=VeDCCR_e_Protocol_Priority{1..3}.Value
              IN_VeDCCR_e_SOC_OOR_Value: accessed-variable=VeDCCR_e_SOC_OOR.Value
              IN_VeDCCR_e_SelEnrgyTxType_Value: accessed-variable=VeDCCR_e_SelEnrgyTxType.Value
              IN_VeDCCR_e_SelPayOptn_Value: accessed-variable=VeDCCR_e_SelPayOptn.Value
              IN_VeDCCR_e_SelectAppProtocol_Value: accessed-variable=VeDCCR_e_SelectAppProtocol.Value
              IN_VeDCCR_e_Service_Category_Value: accessed-variable=VeDCCR_e_Service_Category.Value
              IN_VeDCCR_k_MaxEntriesSASScheduleTuple_Value: accessed-variable=VeDCCR_k_MaxEntriesSASScheduleTuple.Value
              IN_VeDMAB_y_StatusByte_LostCommBCCM_Value: accessed-variable=VeDMAB_y_StatusByte_LostCommBCCM.Value
              IN_VeDMAB_y_StatusByte_LostCommIDCM_Value: accessed-variable=VeDMAB_y_StatusByte_LostCommIDCM.Value
              IN_VeDMAB_y_StatusByte_LostCommOBCM_Value: accessed-variable=VeDMAB_y_StatusByte_LostCommOBCM.Value
              IN_VeDMAB_y_StatusByte_LostComm_IDCM_CANC11_Value: accessed-variable=VeDMAB_y_StatusByte_LostComm_IDCM_CANC11.Value
              IN_VeENGR_T_EngCoolantTemp_Value: accessed-variable=VeENGR_T_EngCoolantTemp.Value, variation-point={short-label=vpIN_VeENGR_T_EngCoolantTemp_Value, sw-syscond=1}
              IN_VeENGR_b_ECT_Sgnl_Rcvd_Value: accessed-variable=VeENGR_b_ECT_Sgnl_Rcvd.Value, variation-point={short-label=vpIN_VeENGR_b_ECT_Sgnl_Rcvd_Value, sw-syscond=1}
              IN_VeESMR_P_BattLTMaxLim_Value: accessed-variable=VeESMR_P_BattLTMaxLim.Value, variation-point={short-label=vpIN_VeESMR_P_BattLTMaxLim_Value, sw-syscond=1}
              IN_VeESMR_Pct_IP_SOCSetPt_Value: accessed-variable=VeESMR_Pct_IP_SOCSetPt.Value, variation-point={short-label=vpIN_VeESMR_Pct_IP_SOCSetPt_Value, sw-syscond=1}
              IN_VeESMR_Pct_Logistics_SOCSetPt_Value: accessed-variable=VeESMR_Pct_Logistics_SOCSetPt.Value, variation-point={short-label=vpIN_VeESMR_Pct_Logistics_SOCSetPt_Value, sw-syscond=1}
              IN_VeESSR_e_EngStartStopSt_Value: accessed-variable=VeESSR_e_EngStartStopSt.Value, variation-point={short-label=vpIN_VeESSR_e_EngStartStopSt_Value, sw-syscond=1}
              IN_VeFCPR_b_FCPS_H2_RefuelSts_Value: accessed-variable=VeFCPR_b_FCPS_H2_RefuelSts.Value, variation-point={short-label=vpIN_VeFCPR_b_FCPS_H2_RefuelSts_Value, sw-syscond=1}
              IN_VeFSCR_b_HVFuncRejHdAjar_Value: accessed-variable=VeFSCR_b_HVFuncRejHdAjar.Value, variation-point={short-label=vpIN_VeFSCR_b_HVFuncRejHdAjar_Value, sw-syscond=1}
              IN_VeFSCR_b_HoodAjarBatCrit_Value: accessed-variable=VeFSCR_b_HoodAjarBatCrit.Value
              IN_VeHMIR_Pct_HVBatSOC_HCP_Value: accessed-variable=VeHMIR_Pct_HVBatSOC_HCP.Value, variation-point={short-label=vpIN_VeHMIR_Pct_HVBatSOC_HCP_Value, sw-syscond=1}
              IN_VeHPMR_b_BattCntctrOpenPndg_Value: accessed-variable=VeHPMR_b_BattCntctrOpenPndg.Value, variation-point={short-label=vpIN_VeHPMR_b_BattCntctrOpenPndg_Value, sw-syscond=1}
              IN_VeHPMR_b_PropSysActv_Value: accessed-variable=VeHPMR_b_PropSysActv.Value
              IN_VeHSWR_b_HoodOpen_Value: accessed-variable=VeHSWR_b_HoodOpen.Value
              IN_VeHVTR_I_AccPwrModCurr_Value: accessed-variable=VeHVTR_I_AccPwrModCurr.Value
              IN_VeHVTR_P_AccPwrModPwr_Value: accessed-variable=VeHVTR_P_AccPwrModPwr.Value, variation-point={short-label=vpIN_VeHVTR_P_AccPwrModPwr_Value, sw-syscond=1}
              IN_VeHVTR_P_HV_AccPwr_Value: accessed-variable=VeHVTR_P_HV_AccPwr.Value, variation-point={short-label=vpIN_VeHVTR_P_HV_AccPwr_Value, sw-syscond=1}
              IN_VeHVTR_U_HV_BatVoltModMaxArb_Value: accessed-variable=VeHVTR_U_HV_BatVoltModMaxArb.Value
              IN_VeHVTR_U_HvBattVolt_Min_Value: accessed-variable=VeHVTR_U_HvBattVolt_Min.Value, variation-point={short-label=vpIN_VeHVTR_U_HvBattVolt_Min_Value, sw-syscond=1}
              IN_VeIDCR_I_EVSECurr_RegTol_Value: accessed-variable=VeIDCR_I_EVSECurr_RegTol.Value
              IN_VeIDCR_I_EVSEOutputCurr_Value: accessed-variable=VeIDCR_I_EVSEOutputCurr.Value
              IN_VeIDCR_I_EVSEPeakCurrRip_Value: accessed-variable=VeIDCR_I_EVSEPeakCurrRip.Value
              IN_VeIDCR_I_J1772InputCrntAval_Value: accessed-variable=VeIDCR_I_J1772InputCrntAval.Value, variation-point={short-label=vpIN_VeIDCR_I_J1772InputCrntAval_Value, sw-syscond=1}
              IN_VeIDCR_U_AC_InputVltOBCM_Value: accessed-variable=VeIDCR_U_AC_InputVltOBCM.Value, variation-point={short-label=vpIN_VeIDCR_U_AC_InputVltOBCM_Value, sw-syscond=1}
              IN_VeIDCR_b_AC_LnHi_Value: accessed-variable=VeIDCR_b_AC_LnHi.Value, variation-point={short-label=vpIN_VeIDCR_b_AC_LnHi_Value, sw-syscond=1}
              IN_VeIDCR_b_AC_LnLow_Value: accessed-variable=VeIDCR_b_AC_LnLow.Value, variation-point={short-label=vpIN_VeIDCR_b_AC_LnLow_Value, sw-syscond=1}
              IN_VeIDCR_b_ChrgEnblOBCM_Value: accessed-variable=VeIDCR_b_ChrgEnblOBCM.Value
              IN_VeIDCR_b_IDCM_DCCA_Value: accessed-variable=VeIDCR_b_IDCM_DCCA.Value
              IN_VeIDCR_b_J1772_S2_Status_Value: accessed-variable=VeIDCR_b_J1772_S2_Status.Value, variation-point={short-label=vpIN_VeIDCR_b_J1772_S2_Status_Value, sw-syscond=1}
              IN_VeIDCR_b_V2L_Detected_Value: accessed-variable=VeIDCR_b_V2L_Detected.Value
              IN_VeIDCR_b_V2X_Sts_Value: accessed-variable=VeIDCR_b_V2X_Sts.Value, variation-point={short-label=vpIN_VeIDCR_b_V2X_Sts_Value, sw-syscond=1}
              IN_VeIDCR_e_ChrgrModeStat_OBCM_Value: accessed-variable=VeIDCR_e_ChrgrModeStat_OBCM.Value, variation-point={short-label=vpIN_VeIDCR_e_ChrgrModeStat_OBCM_Value, sw-syscond=1}
              IN_VeIDCR_e_EVSE_PilotStat_OBCM_Value: accessed-variable=VeIDCR_e_EVSE_PilotStat_OBCM.Value
              IN_VeIDCR_e_ProxStat_Value: accessed-variable=VeIDCR_e_ProxStat.Value
              IN_VeIDCR_e_Prox_GBT_Value: accessed-variable=VeIDCR_e_Prox_GBT.Value
              IN_VeIDCR_e_SLACSts_Value: accessed-variable=VeIDCR_e_SLACSts.Value
              IN_VeIDCR_e_TxGBTMsgRequest_Value: accessed-variable=VeIDCR_e_TxGBTMsgRequest.Value
              IN_VeIDCR_e_TxGBTMsgResponse_Value: accessed-variable=VeIDCR_e_TxGBTMsgResponse.Value
              IN_VeINVR_I_MtrA_DC_Crnt_Value: accessed-variable=VeINVR_I_MtrA_DC_Crnt.Value, variation-point={short-label=vpIN_VeINVR_I_MtrA_DC_Crnt_Value, sw-syscond=1}
              IN_VeINVR_U_MtrA_DC_Volt_Value: accessed-variable=VeINVR_U_MtrA_DC_Volt.Value, variation-point={short-label=vpIN_VeINVR_U_MtrA_DC_Volt_Value, sw-syscond=1}
              IN_VeOFCR_I_ChrgPortOTCrnt_Value: accessed-variable=VeOFCR_I_ChrgPortOTCrnt.Value, variation-point={short-label=vpIN_VeOFCR_I_ChrgPortOTCrnt_Value, sw-syscond=1}
              IN_VePLTR_b_InFieldMode_Value: accessed-variable=VePLTR_b_InFieldMode.Value
              IN_VePLTR_e_ShippingMode_Value: accessed-variable=VePLTR_e_ShippingMode.Value
              IN_VePMDR_e_PMM_PowerMode_Value: accessed-variable=VePMDR_e_PMM_PowerMode.Value, variation-point={short-label=vpIN_VePMDR_e_PMM_PowerMode_Value, sw-syscond=1}
              IN_VeSCPR_b_ChargeReq_Value: accessed-variable=VeSCPR_b_ChargeReq.Value
              IN_VeSRAR_b_StpCharging_Value: accessed-variable=VeSRAR_b_StpCharging.Value, variation-point={short-label=vpIN_VeSRAR_b_StpCharging_Value, sw-syscond=1}
              IN_VeSSDR_b_CabPrecDny_BattCond_Value: accessed-variable=VeSSDR_b_CabPrecDny_BattCond.Value
              IN_VeSSDR_b_DsblHVBattChrg_Value: accessed-variable=VeSSDR_b_DsblHVBattChrg.Value, variation-point={short-label=vpIN_VeSSDR_b_DsblHVBattChrg_Value, sw-syscond=1}
              IN_VeSSDR_b_HVBatPerWUThermal_Value: accessed-variable=VeSSDR_b_HVBatPerWUThermal.Value
              IN_VeSSDR_b_KeepHotCold_PCC_Value: accessed-variable=VeSSDR_b_KeepHotCold_PCC.Value, variation-point={short-label=vpIN_VeSSDR_b_KeepHotCold_PCC_Value, sw-syscond=1}
              IN_VeTHMR_b_RdyForShtDwn_Value: accessed-variable=VeTHMR_b_RdyForShtDwn.Value
              IN_VeTIMR_e_RacePrep_Value: accessed-variable=VeTIMR_e_RacePrep.Value, variation-point={short-label=vpIN_VeTIMR_e_RacePrep_Value, sw-syscond=1}
              IN_VeTIMR_e_RacePrepRaceTypeSts_Value: accessed-variable=VeTIMR_e_RacePrepRaceTypeSts.Value, variation-point={short-label=vpIN_VeTIMR_e_RacePrepRaceTypeSts_Value, sw-syscond=1}
              IN_VeVDVR_b_DschrgS2Cmd_Value: accessed-variable=VeVDVR_b_DschrgS2Cmd.Value, variation-point={short-label=vpIN_VeVDVR_b_DschrgS2Cmd_Value, sw-syscond=1}
              IN_VeVDVR_b_Secure_V2LConnected_Value: accessed-variable=VeVDVR_b_Secure_V2LConnected.Value, variation-point={short-label=vpIN_VeVDVR_b_Secure_V2LConnected_Value, sw-syscond=1}
              IN_VeVDVR_b_Secure_V2VConnected_Value: accessed-variable=VeVDVR_b_Secure_V2VConnected.Value, variation-point={short-label=vpIN_VeVDVR_b_Secure_V2VConnected_Value, sw-syscond=1}
              IN_VeVDVR_b_V2VChrgPortReq_Value: accessed-variable=VeVDVR_b_V2VChrgPortReq.Value, variation-point={short-label=vpIN_VeVDVR_b_V2VChrgPortReq_Value, sw-syscond=1}
              IN_VeVDVR_b_V2V_Detected_Value: accessed-variable=VeVDVR_b_V2V_Detected.Value, variation-point={short-label=vpIN_VeVDVR_b_V2V_Detected_Value, sw-syscond=1}
              IN_VeVDVR_e_DschrgOBCMdRq_Value: accessed-variable=VeVDVR_e_DschrgOBCMdRq.Value
              IN_VeVTHR_b_Rdy4shutdown_Value: accessed-variable=VeVTHR_b_Rdy4shutdown.Value, variation-point={short-label=vpIN_VeVTHR_b_Rdy4shutdown_Value, sw-syscond=1}
              IN_VeVTHR_b_V2H_Active_Value: accessed-variable=VeVTHR_b_V2H_Active.Value, variation-point={short-label=vpIN_VeVTHR_b_V2H_Active_Value, sw-syscond=1}
              IN_VeVTLR_b_ACSwSts_Value: accessed-variable=VeVTLR_b_ACSwSts.Value, variation-point={short-label=vpIN_VeVTLR_b_ACSwSts_Value, sw-syscond=1}
              IN_VeVTLR_b_DschrgS2Cmd_Value: accessed-variable=VeVTLR_b_DschrgS2Cmd.Value
              IN_VeVTLR_b_OnboardPP1_Dtctd_Value: accessed-variable=VeVTLR_b_OnboardPP1_Dtctd.Value
              IN_VeVTLR_e_DschrgOBCMdRq_Value: accessed-variable=VeVTLR_e_DschrgOBCMdRq.Value
              IN_VeVTLR_e_DschrgOBCMdRq_Onboard_Value: accessed-variable=VeVTLR_e_DschrgOBCMdRq_Onboard.Value
              IN_VeVTLR_e_DschrgSysSts_Value: accessed-variable=VeVTLR_e_DschrgSysSts.Value
          data-send-points:
            133 x access:
              OUT_VeOBCR_b_PluggedIn_EEPROM_Value: accessed-variable=VeOBCR_b_PluggedIn_EEPROM.Value
              OUT_VeOBCR_e_ChargingSystemSts_Value: accessed-variable=VeOBCR_e_ChargingSystemSts.Value
              OUT_VeOBCR_t_EstTimeofChrg_Lv2_Value: accessed-variable=VeOBCR_t_EstTimeofChrg_Lv2.Value
              OUT_VeOBCR_t_EstTimeofChrg_Lv1_Value: accessed-variable=VeOBCR_t_EstTimeofChrg_Lv1.Value
              OUT_VeOBCR_e_ChargingLevel_Value: accessed-variable=VeOBCR_e_ChargingLevel.Value
              OUT_VeOBCR_e_ChrgrModeReq_Value: accessed-variable=VeOBCR_e_ChrgrModeReq.Value
              OUT_VeOBCR_e_ChrgrTrsfMethodReq_Value: accessed-variable=VeOBCR_e_ChrgrTrsfMethodReq.Value
              OUT_VeOBCR_I_MaxAllowableCrntAC_Value: accessed-variable=VeOBCR_I_MaxAllowableCrntAC.Value
              OUT_VeOBCR_U_MinAllowableBattVolt_Value: accessed-variable=VeOBCR_U_MinAllowableBattVolt.Value
              OUT_VeOBCR_U_MaxAllowableBattVolt_Value: accessed-variable=VeOBCR_U_MaxAllowableBattVolt.Value
              OUT_VeOBCR_I_MaxAllowableCrntBatt_Value: accessed-variable=VeOBCR_I_MaxAllowableCrntBatt.Value
              OUT_VeOBCR_b_EnblChrg_Value: accessed-variable=VeOBCR_b_EnblChrg.Value
              OUT_VeOBCR_b_CloseS2Cntctr_Value: accessed-variable=VeOBCR_b_CloseS2Cntctr.Value
              OUT_VeOBCR_b_RdyForShtDwn_Value: accessed-variable=VeOBCR_b_RdyForShtDwn.Value
              OUT_VeOBCR_e_ChrgSysShtDwnFlt_Value: accessed-variable=VeOBCR_e_ChrgSysShtDwnFlt.Value
              OUT_VeOBCR_P_AvalPwrForThmr_Value: accessed-variable=VeOBCR_P_AvalPwrForThmr.Value
              OUT_VeOBCR_Pct_TargetSOC_Value: accessed-variable=VeOBCR_Pct_TargetSOC.Value
              OUT_VeOBCR_b_EnableCANC_Value: accessed-variable=VeOBCR_b_EnableCANC.Value
              OUT_VeOBCR_b_SecureConEst_Value: accessed-variable=VeOBCR_b_SecureConEst.Value
              OUT_VeOBCR_b_ChrgPort_BCM_Cmd_Value: accessed-variable=VeOBCR_b_ChrgPort_BCM_Cmd.Value
              OUT_VeOBCR_b_SmartEvse_Dtctd_Value: accessed-variable=VeOBCR_b_SmartEvse_Dtctd.Value
              OUT_VeOBCR_b_ValidPluginDetected_Value: accessed-variable=VeOBCR_b_ValidPluginDetected.Value
              OUT_VeOBCR_b_PluggedIn_Value: accessed-variable=VeOBCR_b_PluggedIn.Value
              OUT_VeOBCR_P_Est_PowerBudget_Value: accessed-variable=VeOBCR_P_Est_PowerBudget.Value
              OUT_VeOBCR_E_EVEnergyRequest_Value: accessed-variable=VeOBCR_E_EVEnergyRequest.Value
              OUT_VeOBCR_b_ChargingComplete_Value: accessed-variable=VeOBCR_b_ChargingComplete.Value
              OUT_VeOBCR_t_RemTimeToFullSOC_Value: accessed-variable=VeOBCR_t_RemTimeToFullSOC.Value
              OUT_VeOBCR_e_HCP_DC_Retry_Value: accessed-variable=VeOBCR_e_HCP_DC_Retry.Value
              OUT_VeOBCR_e_ChargeType_Value: accessed-variable=VeOBCR_e_ChargeType.Value
              OUT_VeOBCR_t_EstTimeDCFastChrg_100_Value: accessed-variable=VeOBCR_t_EstTimeDCFastChrg_100.Value
              OUT_VeOBCR_t_EstTimeDCFastChrg_80_Value: accessed-variable=VeOBCR_t_EstTimeDCFastChrg_80.Value
              OUT_VeOBCR_e_ChrgSysStat_SF_Value: accessed-variable=VeOBCR_e_ChrgSysStat_SF.Value
              OUT_VeOBCR_I_ChrgCurrEstSOC_Value: accessed-variable=VeOBCR_I_ChrgCurrEstSOC.Value
              OUT_VeOBCR_b_EnablePowerTransfer_Value: accessed-variable=VeOBCR_b_EnablePowerTransfer.Value
              OUT_VeOBCR_b_SecureConnV2L_Value: accessed-variable=VeOBCR_b_SecureConnV2L.Value
              OUT_VeOBCR_b_BPCM_Rdy_Value: accessed-variable=VeOBCR_b_BPCM_Rdy.Value
              OUT_VeOBCR_b_RacePrepBattLvlSts_Value: accessed-variable=VeOBCR_b_RacePrepBattLvlSts.Value
              OUT_VeOBCR_t_RemTimeToBulkSOC_Value: accessed-variable=VeOBCR_t_RemTimeToBulkSOC.Value
              OUT_VeOBCR_e_ChrgPort_Req_Value: accessed-variable=VeOBCR_e_ChrgPort_Req.Value
              OUT_VeOBCR_b_RelockTimerActive_Value: accessed-variable=VeOBCR_b_RelockTimerActive.Value
              OUT_VeOBCR_b_Lock_Status_Value: accessed-variable=VeOBCR_b_Lock_Status.Value
              OUT_VeOBCR_k_ChrgPortEnbl_BSW_Value: accessed-variable=VeOBCR_k_ChrgPortEnbl_BSW.Value
              OUT_VeOBCR_b_ChrgPortReq_BSW_Value: accessed-variable=VeOBCR_b_ChrgPortReq_BSW.Value
              OUT_VeOBCR_b_DVC_ChrgPort_Req_Value: accessed-variable=VeOBCR_b_DVC_ChrgPort_Req.Value
              OUT_VeOBCR_b_HMIR_MSG13_Value: accessed-variable=VeOBCR_b_HMIR_MSG13.Value
              OUT_VeOBCR_e_ChargeportLock_Sts_Value: accessed-variable=VeOBCR_e_ChargeportLock_Sts.Value
              OUT_VeOBCR_I_ChrgCrntReqDelta_Value: accessed-variable=VeOBCR_I_ChrgCrntReqDelta.Value
              OUT_VeOBCR_e_HVBattBalReq_Value: accessed-variable=VeOBCR_e_HVBattBalReq.Value
              OUT_VeOBCR_I_MaxAllowedCurr_Value: accessed-variable=VeOBCR_I_MaxAllowedCurr.Value
              OUT_VeOBCR_e_BattPckVoltRchd_BST_Value: accessed-variable=VeOBCR_e_BattPckVoltRchd_BST.Value
              OUT_VeOBCR_e_SOCRchd_BST_Value: accessed-variable=VeOBCR_e_SOCRchd_BST.Value
              OUT_VeOBCR_e_MaxCellVoltRchd_BST_Value: accessed-variable=VeOBCR_e_MaxCellVoltRchd_BST.Value
              OUT_VeOBCR_P_PLS_PwrLev{1..5}_Value: accessed-variable=VeOBCR_P_PLS_PwrLev{1..5}.Value
              OUT_VeOBCR_e_PwrLevSet_Value: accessed-variable=VeOBCR_e_PwrLevSet.Value
              OUT_VeOBCR_b_ChrgSysFault_Value: accessed-variable=VeOBCR_b_ChrgSysFault.Value
              OUT_VeOBCR_U_ChrgVltReqDelta_Value: accessed-variable=VeOBCR_U_ChrgVltReqDelta.Value
              OUT_VeOBCR_k_ChrgSysFault_Reason_Value: accessed-variable=VeOBCR_k_ChrgSysFault_Reason.Value
              OUT_VeOBCR_I_BattSideCurr_Value: accessed-variable=VeOBCR_I_BattSideCurr.Value
              OUT_VeOBCR_b_ChargeReq_ToBPCM_Value: accessed-variable=VeOBCR_b_ChargeReq_ToBPCM.Value
              OUT_VeOBCR_b_HMIR_MSG5_Value: accessed-variable=VeOBCR_b_HMIR_MSG5.Value
              OUT_VeOBCR_b_HMIR_MSG6_Value: accessed-variable=VeOBCR_b_HMIR_MSG6.Value
              OUT_VeOBCR_b_HMIR_MSG8_Value: accessed-variable=VeOBCR_b_HMIR_MSG8.Value
              OUT_VeOBCR_b_ChrgSysFaultBPCM_Value: accessed-variable=VeOBCR_b_ChrgSysFaultBPCM.Value
              OUT_VeOBCR_K_ChargingFailure{1..5}_Value: accessed-variable=VeOBCR_K_ChargingFailure{1..5}.Value
              OUT_VeOBCR_e_Service_Category_Value: accessed-variable=VeOBCR_e_Service_Category.Value
              OUT_VeOBCR_e_SelEnrgyTxType_Value: accessed-variable=VeOBCR_e_SelEnrgyTxType.Value
              OUT_VeOBCR_b_EVReady_Value: accessed-variable=VeOBCR_b_EVReady.Value
              OUT_VeOBCR_e_HCP_EVErrorCode_Value: accessed-variable=VeOBCR_e_HCP_EVErrorCode.Value
              OUT_VeOBCR_I_EVMax_I_Limit_Value: accessed-variable=VeOBCR_I_EVMax_I_Limit.Value
              OUT_VeOBCR_P_EVMax_P_Limit_Value: accessed-variable=VeOBCR_P_EVMax_P_Limit.Value
              OUT_VeOBCR_U_EVMax_V_Limit_Value: accessed-variable=VeOBCR_U_EVMax_V_Limit.Value
              OUT_VeOBCR_E_EVEnergyCapacity_Value: accessed-variable=VeOBCR_E_EVEnergyCapacity.Value
              OUT_VeOBCR_b_DC_Isolation_Cmd_Value: accessed-variable=VeOBCR_b_DC_Isolation_Cmd.Value
              OUT_VeOBCR_e_DC_CntctrCmd_Value: accessed-variable=VeOBCR_e_DC_CntctrCmd.Value
              OUT_VeOBCR_U_EV_DCTargetVolt_Value: accessed-variable=VeOBCR_U_EV_DCTargetVolt.Value
              OUT_VeOBCR_b_WeldChkComplete_Value: accessed-variable=VeOBCR_b_WeldChkComplete.Value
              OUT_VeOBCR_b_RdyToChrgSt_Value: accessed-variable=VeOBCR_b_RdyToChrgSt.Value
              OUT_VeOBCR_K_SelectedServiceID_Value: accessed-variable=VeOBCR_K_SelectedServiceID.Value
              OUT_VeOBCR_e_SelPayOptn_Value: accessed-variable=VeOBCR_e_SelPayOptn.Value
              OUT_VeOBCR_b_HCP_SessionStpCmd_Value: accessed-variable=VeOBCR_b_HCP_SessionStpCmd.Value
              OUT_VeOBCR_e_DCChrg_TestSts_Value: accessed-variable=VeOBCR_e_DCChrg_TestSts.Value
              OUT_VeOBCR_b_DCChrgInitialization_Value: accessed-variable=VeOBCR_b_DCChrgInitialization.Value
              OUT_VeOBCR_e_CellVolt_OOR_Value: accessed-variable=VeOBCR_e_CellVolt_OOR.Value
              OUT_VeOBCR_e_ChrgCurr_OOR_Value: accessed-variable=VeOBCR_e_ChrgCurr_OOR.Value
              OUT_VeOBCR_e_BattTemp_OOR_Value: accessed-variable=VeOBCR_e_BattTemp_OOR.Value
              OUT_VeOBCR_e_SOC_OOR_Value: accessed-variable=VeOBCR_e_SOC_OOR.Value
              OUT_VeOBCR_b_CPIM_Error_Value: accessed-variable=VeOBCR_b_CPIM_Error.Value
              OUT_VeOBCR_b_CPIM_OT_Value: accessed-variable=VeOBCR_b_CPIM_OT.Value
              OUT_VeOBCR_Pct_BattFullSOC_Value: accessed-variable=VeOBCR_Pct_BattFullSOC.Value
              OUT_VeOBCR_b_BattOverVolt_Value: accessed-variable=VeOBCR_b_BattOverVolt.Value
              OUT_VeOBCR_b_BattUnderVolt_Value: accessed-variable=VeOBCR_b_BattUnderVolt.Value
              OUT_VeOBCR_b_DCGBTReadyToCharge_Value: accessed-variable=VeOBCR_b_DCGBTReadyToCharge.Value
              OUT_VeOBCR_b_DCGBTEVChrgPermit_Value: accessed-variable=VeOBCR_b_DCGBTEVChrgPermit.Value
              OUT_VeOBCR_T_GBT_MaxBattTempAllwd_Value: accessed-variable=VeOBCR_T_GBT_MaxBattTempAllwd.Value
              OUT_VeOBCR_e_GBT_ChrgCntrolMethod_Value: accessed-variable=VeOBCR_e_GBT_ChrgCntrolMethod.Value
              OUT_VeOBCR_e_GBT_ChrgrInterrupt_Value: accessed-variable=VeOBCR_e_GBT_ChrgrInterrupt.Value
              OUT_VeOBCR_e_SelectAppProtocol_Value: accessed-variable=VeOBCR_e_SelectAppProtocol.Value
              OUT_VeOBCR_b_SelectSecProtocol_Value: accessed-variable=VeOBCR_b_SelectSecProtocol.Value
              OUT_VeOBCR_e_ChargeProgress_Value: accessed-variable=VeOBCR_e_ChargeProgress.Value
              OUT_VeOBCR_e_DC_ChrgTypeCmd_Value: accessed-variable=VeOBCR_e_DC_ChrgTypeCmd.Value
              OUT_VeOBCR_Cnt_PlugIn_Reason_Value: accessed-variable=VeOBCR_Cnt_PlugIn_Reason.Value
              OUT_VaOBCR_Cnt_PlugIn_Vector_Value: accessed-variable=VaOBCR_Cnt_PlugIn_Vector.Value
              OUT_VeOBCR_b_ChrgrLOC_Value: accessed-variable=VeOBCR_b_ChrgrLOC.Value
              OUT_VeOBCR_b_PlugInLock_Value: accessed-variable=VeOBCR_b_PlugInLock.Value
              OUT_VaOBCR_b_NCR_Signals_Value: accessed-variable=VaOBCR_b_NCR_Signals.Value
              OUT_VeOBCR_Cnt_InitChecks_Reason_Value: accessed-variable=VeOBCR_Cnt_InitChecks_Reason.Value
              OUT_VeOBCR_b_EnableChargeDC_Value: accessed-variable=VeOBCR_b_EnableChargeDC.Value
              OUT_VaOBCR_k_InitChecks_Vector_Value: accessed-variable=VaOBCR_k_InitChecks_Vector.Value
              OUT_VeOBCR_Cnt_NCR_Value: accessed-variable=VeOBCR_Cnt_NCR.Value
              OUT_VeOBCR_b_EnblDC_GBT_Value: accessed-variable=VeOBCR_b_EnblDC_GBT.Value
              OUT_VeOBCR_b_EnblDsblProxPlg_Value: accessed-variable=VeOBCR_b_EnblDsblProxPlg.Value
              OUT_VeOBCR_P_EVSEPwr_Value: accessed-variable=VeOBCR_P_EVSEPwr.Value
              OUT_VeOBCR_P_PowertoBattery_Value: accessed-variable=VeOBCR_P_PowertoBattery.Value
              OUT_VeOBCR_q_BatteryAmpHrCap_Value: accessed-variable=VeOBCR_q_BatteryAmpHrCap.Value
              OUT_VeOBCR_P_ActChargePowerLim_Value: accessed-variable=VeOBCR_P_ActChargePowerLim.Value
              OUT_VeOBCR_P_ActChargePower_Value: accessed-variable=VeOBCR_P_ActChargePower.Value
              OUT_VeOBCR_b_ActChargePowerLimFA_Value: accessed-variable=VeOBCR_b_ActChargePowerLimFA.Value
              OUT_VeOBCR_b_ActChargePowerFA_Value: accessed-variable=VeOBCR_b_ActChargePowerFA.Value
              OUT_VeOBCR_b_PnCFailure_Value: accessed-variable=VeOBCR_b_PnCFailure.Value
              OUT_VeOBCR_b_PnCRetryFail_Value: accessed-variable=VeOBCR_b_PnCRetryFail.Value
              OUT_VeOBCR_e_Protocol_Priority{1..3}_Value: accessed-variable=VeOBCR_e_Protocol_Priority{1..3}.Value
              OUT_VeOBCR_d_ServiceScope_Value: accessed-variable=VeOBCR_d_ServiceScope.Value
              OUT_VeOBCR_k_MaxEntriesSASScheduleTuple_Value: accessed-variable=VeOBCR_k_MaxEntriesSASScheduleTuple.Value
          30 x parameter access:
            CALPRM_HeOBCR_t_FnctRate_HeOBCR_t_FnctRate: accessed-parameter=HeOBCR_t_FnctRate.HeOBCR_t_FnctRate, variation-point={short-label=vpCALPRM_HeOBCR_t_FnctRate_HeOBCR_t_FnctRate, sw-syscond=1}
            CALPRM_HeOBCR_t_dT_HeOBCR_t_dT: accessed-parameter=HeOBCR_t_dT.HeOBCR_t_dT, variation-point={short-label=vpCALPRM_HeOBCR_t_dT_HeOBCR_t_dT, sw-syscond=1}
            CALPRM_KeOBCR_Cnt_LatchUnplugInterupCnt_KeOBCR_Cnt_LatchUnplugInterupCnt: accessed-parameter=KeOBCR_Cnt_LatchUnplugInterupCnt.KeOBCR_Cnt_LatchUnplugInterupCnt, variation-point={short-label=vpCALPRM_KeOBCR_Cnt_LatchUnplugInterupCnt_KeOBCR_Cnt_LatchUnplugInterupCnt, sw-syscond=1}
            CALPRM_KeOBCR_I_MinJ1772ICA_KeOBCR_I_MinJ1772ICA: accessed-parameter=KeOBCR_I_MinJ1772ICA.KeOBCR_I_MinJ1772ICA, variation-point={short-label=vpCALPRM_KeOBCR_I_MinJ1772ICA_KeOBCR_I_MinJ1772ICA, sw-syscond=1}
            CALPRM_KeOBCR_I_MinJ1772ICA1_KeOBCR_I_MinJ1772ICA1: accessed-parameter=KeOBCR_I_MinJ1772ICA1.KeOBCR_I_MinJ1772ICA1, variation-point={short-label=vpCALPRM_KeOBCR_I_MinJ1772ICA1_KeOBCR_I_MinJ1772ICA1, sw-syscond=1}
            CALPRM_KeOBCR_P_ThermalHys_Cal{1..3}_KeOBCR_P_ThermalHys_Cal{1..3}: accessed-parameter=KeOBCR_P_ThermalHys_Cal{1..3}.KeOBCR_P_ThermalHys_Cal{1..3}, variation-point={short-label=vpCALPRM_KeOBCR_P_ThermalHys_Cal{1..3}_KeOBCR_P_ThermalHys_Cal{1..3}, sw-syscond=1}
            CALPRM_KeOBCR_U_MinValue2TrgrPPI_KeOBCR_U_MinValue2TrgrPPI: accessed-parameter=KeOBCR_U_MinValue2TrgrPPI.KeOBCR_U_MinValue2TrgrPPI, variation-point={short-label=vpCALPRM_KeOBCR_U_MinValue2TrgrPPI_KeOBCR_U_MinValue2TrgrPPI, sw-syscond=1}
            CALPRM_KeOBCR_k_ChargingSts_KeOBCR_k_ChargingSts: accessed-parameter=KeOBCR_k_ChargingSts.KeOBCR_k_ChargingSts, variation-point={short-label=vpCALPRM_KeOBCR_k_ChargingSts_KeOBCR_k_ChargingSts, sw-syscond=1}
            CALPRM_KeOBCR_t_BPCM_Ready_KeOBCR_t_BPCM_Ready: accessed-parameter=KeOBCR_t_BPCM_Ready.KeOBCR_t_BPCM_Ready, variation-point={short-label=vpCALPRM_KeOBCR_t_BPCM_Ready_KeOBCR_t_BPCM_Ready, sw-syscond=1}
            CALPRM_KeOBCR_t_BPCM_ReadyDelay_KeOBCR_t_BPCM_ReadyDelay: accessed-parameter=KeOBCR_t_BPCM_ReadyDelay.KeOBCR_t_BPCM_ReadyDelay, variation-point={short-label=vpCALPRM_KeOBCR_t_BPCM_ReadyDelay_KeOBCR_t_BPCM_ReadyDelay, sw-syscond=1}
            CALPRM_KeOBCR_t_ChargeCompleteDelay_KeOBCR_t_ChargeCompleteDelay: accessed-parameter=KeOBCR_t_ChargeCompleteDelay.KeOBCR_t_ChargeCompleteDelay, variation-point={short-label=vpCALPRM_KeOBCR_t_ChargeCompleteDelay_KeOBCR_t_ChargeCompleteDelay, sw-syscond=1}
            CALPRM_KeOBCR_t_CloseS2_KeOBCR_t_CloseS2: accessed-parameter=KeOBCR_t_CloseS2.KeOBCR_t_CloseS2, variation-point={short-label=vpCALPRM_KeOBCR_t_CloseS2_KeOBCR_t_CloseS2, sw-syscond=1}
            CALPRM_KeOBCR_t_CloseS2Delay_KeOBCR_t_CloseS2Delay: accessed-parameter=KeOBCR_t_CloseS2Delay.KeOBCR_t_CloseS2Delay, variation-point={short-label=vpCALPRM_KeOBCR_t_CloseS2Delay_KeOBCR_t_CloseS2Delay, sw-syscond=1}
            CALPRM_KeOBCR_t_DCGBTInitWait_KeOBCR_t_DCGBTInitWait: accessed-parameter=KeOBCR_t_DCGBTInitWait.KeOBCR_t_DCGBTInitWait, variation-point={short-label=vpCALPRM_KeOBCR_t_DCGBTInitWait_KeOBCR_t_DCGBTInitWait, sw-syscond=1}
            CALPRM_KeOBCR_t_DCInitWait_KeOBCR_t_DCInitWait: accessed-parameter=KeOBCR_t_DCInitWait.KeOBCR_t_DCInitWait, variation-point={short-label=vpCALPRM_KeOBCR_t_DCInitWait_KeOBCR_t_DCInitWait, sw-syscond=1}
            CALPRM_KeOBCR_t_DCMaxTime_KeOBCR_t_DCMaxTime: accessed-parameter=KeOBCR_t_DCMaxTime.KeOBCR_t_DCMaxTime, variation-point={short-label=vpCALPRM_KeOBCR_t_DCMaxTime_KeOBCR_t_DCMaxTime, sw-syscond=1}
            CALPRM_KeOBCR_t_DbncTmPPI_KeOBCR_t_DbncTmPPI: accessed-parameter=KeOBCR_t_DbncTmPPI.KeOBCR_t_DbncTmPPI, variation-point={short-label=vpCALPRM_KeOBCR_t_DbncTmPPI_KeOBCR_t_DbncTmPPI, sw-syscond=1}
            CALPRM_KeOBCR_t_EnableChargeDelay_KeOBCR_t_EnableChargeDelay: accessed-parameter=KeOBCR_t_EnableChargeDelay.KeOBCR_t_EnableChargeDelay, variation-point={short-label=vpCALPRM_KeOBCR_t_EnableChargeDelay_KeOBCR_t_EnableChargeDelay, sw-syscond=1}
            CALPRM_KeOBCR_t_OBCM_Charge_KeOBCR_t_OBCM_Charge: accessed-parameter=KeOBCR_t_OBCM_Charge.KeOBCR_t_OBCM_Charge, variation-point={short-label=vpCALPRM_KeOBCR_t_OBCM_Charge_KeOBCR_t_OBCM_Charge, sw-syscond=1}
            CALPRM_KeOBCR_t_OBCM_ChargeDelay_KeOBCR_t_OBCM_ChargeDelay: accessed-parameter=KeOBCR_t_OBCM_ChargeDelay.KeOBCR_t_OBCM_ChargeDelay, variation-point={short-label=vpCALPRM_KeOBCR_t_OBCM_ChargeDelay_KeOBCR_t_OBCM_ChargeDelay, sw-syscond=1}
            CALPRM_KeOBCR_t_OBCM_EnblCharge_KeOBCR_t_OBCM_EnblCharge: accessed-parameter=KeOBCR_t_OBCM_EnblCharge.KeOBCR_t_OBCM_EnblCharge, variation-point={short-label=vpCALPRM_KeOBCR_t_OBCM_EnblCharge_KeOBCR_t_OBCM_EnblCharge, sw-syscond=1}
            CALPRM_KeOBCR_t_OBCM_EnblChargeDelay_KeOBCR_t_OBCM_EnblChargeDelay: accessed-parameter=KeOBCR_t_OBCM_EnblChargeDelay.KeOBCR_t_OBCM_EnblChargeDelay, variation-point={short-label=vpCALPRM_KeOBCR_t_OBCM_EnblChargeDelay_KeOBCR_t_OBCM_EnblChargeDelay, sw-syscond=1}
            CALPRM_KeOBCR_t_OBCM_Idle_KeOBCR_t_OBCM_Idle: accessed-parameter=KeOBCR_t_OBCM_Idle.KeOBCR_t_OBCM_Idle, variation-point={short-label=vpCALPRM_KeOBCR_t_OBCM_Idle_KeOBCR_t_OBCM_Idle, sw-syscond=1}
            CALPRM_KeOBCR_t_OBCM_IdleDelay_KeOBCR_t_OBCM_IdleDelay: accessed-parameter=KeOBCR_t_OBCM_IdleDelay.KeOBCR_t_OBCM_IdleDelay, variation-point={short-label=vpCALPRM_KeOBCR_t_OBCM_IdleDelay_KeOBCR_t_OBCM_IdleDelay, sw-syscond=1}
            CALPRM_KeOBCR_t_PowerUp_KeOBCR_t_PowerUp: accessed-parameter=KeOBCR_t_PowerUp.KeOBCR_t_PowerUp, variation-point={short-label=vpCALPRM_KeOBCR_t_PowerUp_KeOBCR_t_PowerUp, sw-syscond=1}
            CALPRM_KeOBCR_t_RetryDelay_KeOBCR_t_RetryDelay: accessed-parameter=KeOBCR_t_RetryDelay.KeOBCR_t_RetryDelay, variation-point={short-label=vpCALPRM_KeOBCR_t_RetryDelay_KeOBCR_t_RetryDelay, sw-syscond=1}
            CALPRM_KeOBCR_t_StateShutDown_KeOBCR_t_StateShutDown: accessed-parameter=KeOBCR_t_StateShutDown.KeOBCR_t_StateShutDown, variation-point={short-label=vpCALPRM_KeOBCR_t_StateShutDown_KeOBCR_t_StateShutDown, sw-syscond=1}
            CALPRM_KeOBCR_t_ThermHysDbnc_KeOBCR_t_ThermHysDbnc: accessed-parameter=KeOBCR_t_ThermHysDbnc.KeOBCR_t_ThermHysDbnc, variation-point={short-label=vpCALPRM_KeOBCR_t_ThermHysDbnc_KeOBCR_t_ThermHysDbnc, sw-syscond=1}
        OBCR_PwrOff
          data-send-points:
            9 x access:
              OUT_EeOBCR_b_PluggedIn_EeOBCR_b_PluggedIn: accessed-variable=EeOBCR_b_PluggedIn.EeOBCR_b_PluggedIn
              OUT_EeOBCR_t_EstTimeofChrg_Lv1_EeOBCR_t_EstTimeofChrg_Lv1: accessed-variable=EeOBCR_t_EstTimeofChrg_Lv1.EeOBCR_t_EstTimeofChrg_Lv1
              OUT_EeOBCR_t_EstTimeofChrg_Lv2_EeOBCR_t_EstTimeofChrg_Lv2: accessed-variable=EeOBCR_t_EstTimeofChrg_Lv2.EeOBCR_t_EstTimeofChrg_Lv2
              OUT_EeOBCR_e_ChargingSystemSts_EeOBCR_e_ChargingSystemSts: accessed-variable=EeOBCR_e_ChargingSystemSts.EeOBCR_e_ChargingSystemSts
              OUT_EeOBCR_e_ChargingLevel_EeOBCR_e_ChargingLevel: accessed-variable=EeOBCR_e_ChargingLevel.EeOBCR_e_ChargingLevel
              OUT_NeOBCR_b_GoodConnEst_NeOBCR_b_GoodConnEst: accessed-variable=NeOBCR_b_GoodConnEst.NeOBCR_b_GoodConnEst
              OUT_NeOBCR_b_Lvl1Latch_NeOBCR_b_Lvl1Latch: accessed-variable=NeOBCR_b_Lvl1Latch.NeOBCR_b_Lvl1Latch
              OUT_NeOBCR_b_Lvl2Latch_NeOBCR_b_Lvl2Latch: accessed-variable=NeOBCR_b_Lvl2Latch.NeOBCR_b_Lvl2Latch
              OUT_NeOBCR_b_SmartEvse_Detected_NeOBCR_b_SmartEvse_Detected: accessed-variable=NeOBCR_b_SmartEvse_Detected.NeOBCR_b_SmartEvse_Detected
      variation point proxy Variant_OBCR_1: category=CONDITION, condition-access=1
      variation point proxy Variant_OBCR_2: category=CONDITION, condition-access=0
